[part 1 of 2: packages /VehicleProject to /Cluster]
AUTOSAR XML (schema 00048)
standard types defined: boolean, sint16, sint8, uint16, uint32, uint8
package /VehicleProject
  system System
package /TP
  can tp config KAMA_FP_EPT_0303_CAN: communication-cluster=KAMA_FP_EPT_0303, can-tp-ecu{cycle-time-main-function=0.005, ecu-instance=VCU}
    can tp channel TPCH: channel-id=1, channel-mode=FULL-DUPLEX-MODE
    can-tp-connection addressing-format=STANDARD, can-tp-channel=TPCH, data-pdu=AllFunctionRequest_Tp_oKAMA_FP_EPT_0303, receiver=TN_VCU, ta-type=FUNCTIONAL, tp-sdu=AllFunctionRequest_oKAMA_FP_EPT_0303, transmitter=TN_Diag:
      ident AllFunctionRequest_oTN_Diag
    can-tp-connection addressing-format=STANDARD, can-tp-channel=TPCH, data-pdu=OBDFunRequest_Tp_oKAMA_FP_EPT_0303, receiver=TN_VCU, ta-type=FUNCTIONAL, tp-sdu=OBDFunRequest_oKAMA_FP_EPT_0303, transmitter=TN_OBDDiag:
      ident OBDFunRequest_oTN_OBDDiag
    can-tp-connection addressing-format=STANDARD, can-tp-channel=TPCH, data-pdu=UDSFunRequest_Tp_oKAMA_FP_EPT_0303, receiver=TN_VCU, ta-type=FUNCTIONAL, tp-sdu=UDSFunRequest_oKAMA_FP_EPT_0303, transmitter=TN_Diag:
      ident UDSFunRequest_oTN_Diag
    can-tp-connection addressing-format=STANDARD, can-tp-channel=TPCH, data-pdu=OBDRequest_Tp_oKAMA_FP_EPT_0303, flow-control-pdu=OBDResponse_Tp_oKAMA_FP_EPT_0303, receiver=TN_VCU, ta-type=PHYSICAL, tp-sdu=OBDRequest_oKAMA_FP_EPT_0303, transmitter=TN_OBDDiag:
      ident OBDRequest_oTN_VCU
    can-tp-connection addressing-format=STANDARD, can-tp-channel=TPCH, data-pdu=OBDResponse_Tp_oKAMA_FP_EPT_0303, flow-control-pdu=OBDRequest_Tp_oKAMA_FP_EPT_0303, receiver=TN_OBDDiag, ta-type=PHYSICAL, tp-sdu=OBDResponse_oKAMA_FP_EPT_0303, transmitter=TN_VCU:
      ident OBDResponse_oTN_VCU
    can-tp-connection addressing-format=STANDARD, can-tp-channel=TPCH, data-pdu=UDSRequest_Tp_oKAMA_FP_EPT_0303, flow-control-pdu=UDSResponse_Tp_oKAMA_FP_EPT_0303, receiver=TN_VCU, ta-type=PHYSICAL, tp-sdu=UDSRequest_oKAMA_FP_EPT_0303, transmitter=TN_Diag:
      ident UDSRequest_oTN_VCU
    can-tp-connection addressing-format=STANDARD, can-tp-channel=TPCH, data-pdu=UDSResponse_Tp_oKAMA_FP_EPT_0303, flow-control-pdu=UDSRequest_Tp_oKAMA_FP_EPT_0303, receiver=TN_Diag, ta-type=PHYSICAL, tp-sdu=UDSResponse_oKAMA_FP_EPT_0303, transmitter=TN_VCU:
      ident UDSResponse_oTN_VCU
    can tp node TN_Diag
    can tp node TN_OBDDiag
    can tp node TN_VCU: connector=CN_KAMA_FP_EPT_0303
package /Cluster
  can cluster KAMA_FP_EPSChassis1_0303: baudrate=500000, protocol-name=CAN
    can physical channel CHNL: comm-connectors=CN_KAMA_FP_EPSChassis1_0303
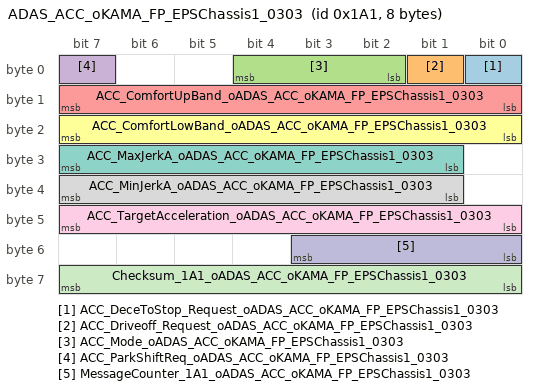
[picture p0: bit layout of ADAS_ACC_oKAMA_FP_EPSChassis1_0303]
      frame ADAS_ACC_oKAMA_FP_EPSChassis1_0303: id 0x1A1, to VCU, frame-length=8, can-addressing-mode=STANDARD
        pdu ADAS_ACC_oKAMA_FP_EPSChassis1_0303: length=8, minimum-delay=0, transmission-mode-false-timing=cyclic-timing={time-offset=0, time-period=0.02}, transmission-mode-true-timing=cyclic-timing={time-offset=0, time-period=0.02}, unused-bit-pattern=0
          signal ACC_DeceToStop_Request_oADAS_ACC_oKAMA_FP_EPSChassis1_0303: start 0, 1 bit, big-endian, i-signal-type=PRIMITIVE, init-value=0, base-type=boolean, compu {0=Cx0_no_demand (no demand), 1=Cx1_demand}, range raw 0..1, transfer-property=PENDING, to VCU
          signal ACC_Driveoff_Request_oADAS_ACC_oKAMA_FP_EPSChassis1_0303: start 1, 1 bit, big-endian, i-signal-type=PRIMITIVE, init-value=0, base-type=boolean, compu {0=Cx0_no_demand (no demand), 1=Cx1_demand}, range raw 0..1, transfer-property=PENDING, to VCU
          signal ACC_Mode_oADAS_ACC_oKAMA_FP_EPSChassis1_0303: start 4, 3 bit, big-endian, i-signal-type=PRIMITIVE, init-value=0, base-type=uint8, compu {0=Cx0_Off, 1=Cx1_passive, 2=Cx2_Standby, 3=Cx3_active, 4=Cx4_BrakeOnly, 5=Cx5_Override, 6=Cx6_Standstill, 7=Cx7_Failure}, range raw 0..7, transfer-property=PENDING, to VCU
          signal ACC_ParkShiftReq_oADAS_ACC_oKAMA_FP_EPSChassis1_0303: start 7, 1 bit, big-endian, i-signal-type=PRIMITIVE, init-value=0, base-type=boolean, compu {0=Cx0_No_Request_ (No Request), 1=Cx1_Request_Park_Shif (Request; Park Shif)}, range raw 0..1, transfer-property=PENDING, to VCU
          signal ACC_ComfortUpBand_oADAS_ACC_oKAMA_FP_EPSChassis1_0303: start 15, 8 bit, big-endian, i-signal-type=PRIMITIVE, init-value=140, base-type=uint8, compu {0=Cx00_no_demand (no demand), 1=Cx01_demand, phys=raw*0.05-7 for raw 2..255}, range raw 0..255, transfer-property=PENDING, to VCU
          signal ACC_ComfortLowBand_oADAS_ACC_oKAMA_FP_EPSChassis1_0303: start 23, 8 bit, big-endian, i-signal-type=PRIMITIVE, init-value=140, base-type=uint8, compu {phys=raw*0.05-7 for raw 0..255}, range raw 0..255, transfer-property=PENDING, to VCU
          signal ACC_MaxJerkA_oADAS_ACC_oKAMA_FP_EPSChassis1_0303: start 31, 7 bit, big-endian, i-signal-type=PRIMITIVE, init-value=0, base-type=uint8, compu {phys=raw*0.2 for raw 0..127}, range raw 0..127, transfer-property=PENDING, to VCU
          signal ACC_MinJerkA_oADAS_ACC_oKAMA_FP_EPSChassis1_0303: start 39, 7 bit, big-endian, i-signal-type=PRIMITIVE, init-value=127, base-type=uint8, compu {phys=raw*0.2-25.4 for raw 0..127}, range raw 0..127, transfer-property=PENDING, to VCU
          signal ACC_TargetAcceleration_oADAS_ACC_oKAMA_FP_EPSChassis1_0303: start 47, 8 bit, big-endian, i-signal-type=PRIMITIVE, init-value=140, base-type=uint8, compu {phys=raw*0.05-7 for raw 0..255; unit m/s^2}, range raw 0..255, unit=m/s^2, transfer-property=PENDING, to VCU
          signal MessageCounter_1A1_oADAS_ACC_oKAMA_FP_EPSChassis1_0303: start 51, 4 bit, big-endian, i-signal-type=PRIMITIVE, init-value=0, base-type=uint8, compu {identical}, range raw 0..15, transfer-property=PENDING, to VCU
          signal Checksum_1A1_oADAS_ACC_oKAMA_FP_EPSChassis1_0303: start 63, 8 bit, big-endian, i-signal-type=PRIMITIVE, init-value=0, base-type=uint8, compu {identical}, range raw 0..255, transfer-property=PENDING, to VCU
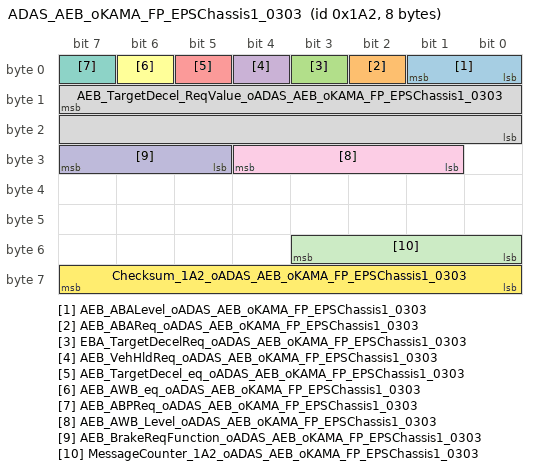
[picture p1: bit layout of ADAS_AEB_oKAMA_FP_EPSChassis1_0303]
      frame ADAS_AEB_oKAMA_FP_EPSChassis1_0303: id 0x1A2, to VCU, frame-length=8, can-addressing-mode=STANDARD
        pdu ADAS_AEB_oKAMA_FP_EPSChassis1_0303: length=8, minimum-delay=0, transmission-mode-false-timing=cyclic-timing={time-offset=0, time-period=0.02}, transmission-mode-true-timing=cyclic-timing={time-offset=0, time-period=0.02}, unused-bit-pattern=0
          signal AEB_ABALevel_oADAS_AEB_oKAMA_FP_EPSChassis1_0303: start 1, 2 bit, big-endian, i-signal-type=PRIMITIVE, init-value=0, base-type=uint8, compu {0=Cx0_Level_0_ (Level 0), 1=Cx1_Level_1 (Level 1), 2=Cx2_Level_2 (Level 2), 3=Cx3_Level_3 (Level 3)}, range raw 0..3, transfer-property=PENDING, to VCU
          signal AEB_ABAReq_oADAS_AEB_oKAMA_FP_EPSChassis1_0303: start 2, 1 bit, big-endian, i-signal-type=PRIMITIVE, init-value=0, base-type=boolean, compu {0=Cx0_No_Request_ (No Request), 1=Cx1_Request}, range raw 0..1, transfer-property=PENDING, to VCU
          signal EBA_TargetDecelReq_oADAS_AEB_oKAMA_FP_EPSChassis1_0303: start 3, 1 bit, big-endian, i-signal-type=PRIMITIVE, init-value=0, base-type=boolean, compu {0=Cx0_No_Request_ (No Request), 1=Cx1_Request}, range raw 0..1, transfer-property=PENDING, to VCU
          signal AEB_VehHldReq_oADAS_AEB_oKAMA_FP_EPSChassis1_0303: start 4, 1 bit, big-endian, i-signal-type=PRIMITIVE, init-value=0, base-type=boolean, compu {0=Cx0_No_Request_ (No Request), 1=Cx1_Request}, range raw 0..1, transfer-property=PENDING, to VCU
          signal AEB_TargetDecel_eq_oADAS_AEB_oKAMA_FP_EPSChassis1_0303: start 5, 1 bit, big-endian, i-signal-type=PRIMITIVE, init-value=0, base-type=boolean, compu {0=Cx0_No_Request_ (No Request), 1=Cx1_Request}, range raw 0..1, transfer-property=PENDING, to VCU
          signal AEB_AWB_eq_oADAS_AEB_oKAMA_FP_EPSChassis1_0303: start 6, 1 bit, big-endian, i-signal-type=PRIMITIVE, init-value=0, base-type=boolean, compu {0=Cx0_No_Request_ (No Request), 1=Cx1_Request}, range raw 0..1, transfer-property=PENDING, to VCU
          signal AEB_ABPReq_oADAS_AEB_oKAMA_FP_EPSChassis1_0303: start 7, 1 bit, big-endian, i-signal-type=PRIMITIVE, init-value=0, base-type=boolean, compu {0=Cx0_No_Request_ (No Request), 1=Cx1_Request}, range raw 0..1, transfer-property=PENDING, to VCU
          signal AEB_TargetDecel_ReqValue_oADAS_AEB_oKAMA_FP_EPSChassis1_0303: start 15, 16 bit, big-endian, i-signal-type=PRIMITIVE, init-value=0, base-type=uint16, compu {0=Cx0000_Valid_value_ (Valid value), 21813=Cx5535_Invalid, phys=raw*0.000488-16 for raw 1..65535; unit m/s2}, range raw 0..65535, unit=m/s2, transfer-property=PENDING, to VCU
          signal AEB_AWB_Level_oADAS_AEB_oKAMA_FP_EPSChassis1_0303: start 28, 4 bit, big-endian, i-signal-type=PRIMITIVE, init-value=0, base-type=uint8, compu {0=Cx0_No_level_ (No level), 1=Cx1_Level_1 (Level 1), 2=Cx2_Level_2 (Level 2), 3=Cx3_Level_3 (Level 3), 4=Cx4_Level_4 (Level 4), 5=Cx5_Resvered}, range raw 0..15, transfer-property=PENDING, to VCU
          signal AEB_BrakeReqFunction_oADAS_AEB_oKAMA_FP_EPSChassis1_0303: start 31, 3 bit, big-endian, i-signal-type=PRIMITIVE, init-value=0, base-type=uint8, compu {0=Cx0_No_Request_ (No Request), 1=Cx1_AEB_V (AEB-V), 2=Cx2_AEB_VRU (AEB-VRU), 3=Cx3_AEB_JA (AEB-JA), 4=Cx4_Reserved, 5=Cx5_AEB_FCTB (AEB-FCTB), 6=Cx6_Reserved}, range raw 0..7, transfer-property=PENDING, to VCU
          signal MessageCounter_1A2_oADAS_AEB_oKAMA_FP_EPSChassis1_0303: start 51, 4 bit, big-endian, i-signal-type=PRIMITIVE, init-value=0, base-type=uint8, compu {identical}, range raw 0..15, transfer-property=PENDING, to VCU
          signal Checksum_1A2_oADAS_AEB_oKAMA_FP_EPSChassis1_0303: start 63, 8 bit, big-endian, i-signal-type=PRIMITIVE, init-value=0, base-type=uint8, compu {identical}, range raw 0..255, transfer-property=PENDING, to VCU
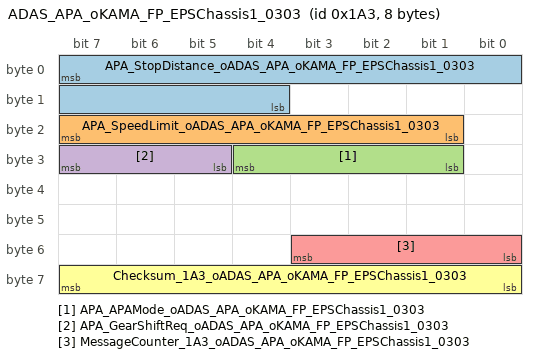
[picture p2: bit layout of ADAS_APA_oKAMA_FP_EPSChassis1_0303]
      frame ADAS_APA_oKAMA_FP_EPSChassis1_0303: id 0x1A3, to VCU, frame-length=8, can-addressing-mode=STANDARD
        pdu ADAS_APA_oKAMA_FP_EPSChassis1_0303: length=8, minimum-delay=0, transmission-mode-false-timing=cyclic-timing={time-offset=0, time-period=0.02}, transmission-mode-true-timing=cyclic-timing={time-offset=0, time-period=0.02}, unused-bit-pattern=0
          signal APA_StopDistance_oADAS_APA_oKAMA_FP_EPSChassis1_0303: start 7, 12 bit, big-endian, i-signal-type=PRIMITIVE, init-value=0, base-type=uint16, compu {identical}, range raw 0..4095, unit=cm, transfer-property=PENDING, to VCU
          signal APA_SpeedLimit_oADAS_APA_oKAMA_FP_EPSChassis1_0303: start 23, 7 bit, big-endian, i-signal-type=PRIMITIVE, init-value=0, base-type=uint8, compu {phys=raw*0.1 for raw 0..127; unit kph}, range raw 0..127, unit=kph, transfer-property=PENDING, to VCU
          signal APA_APAMode_oADAS_APA_oKAMA_FP_EPSChassis1_0303: start 28, 4 bit, big-endian, i-signal-type=PRIMITIVE, init-value=0, base-type=uint8, compu {0=Cx0_Init, 1=Cx1_Standby, 2=Cx2_Active, 3=Cx3_Maneuver_Finished (Maneuver Finished), 4=Cx4_Suspend, 5=Cx5_Abort, 10=CxA_Off}, range raw 0..15, transfer-property=PENDING, to VCU
          signal APA_GearShiftReq_oADAS_APA_oKAMA_FP_EPSChassis1_0303: start 31, 3 bit, big-endian, i-signal-type=PRIMITIVE, init-value=0, base-type=uint8, compu {0=Cx0_No_Request (No Request), 1=Cx1_P, 2=Cx2_R, 3=Cx3_N, 4=Cx4_D}, range raw 0..7, transfer-property=PENDING, to VCU
          signal MessageCounter_1A3_oADAS_APA_oKAMA_FP_EPSChassis1_0303: start 51, 4 bit, big-endian, i-signal-type=PRIMITIVE, init-value=0, base-type=uint8, compu {identical}, range raw 0..15, transfer-property=PENDING, to VCU
          signal Checksum_1A3_oADAS_APA_oKAMA_FP_EPSChassis1_0303: start 63, 8 bit, big-endian, i-signal-type=PRIMITIVE, init-value=0, base-type=uint8, compu {identical}, range raw 0..255, transfer-property=PENDING, to VCU
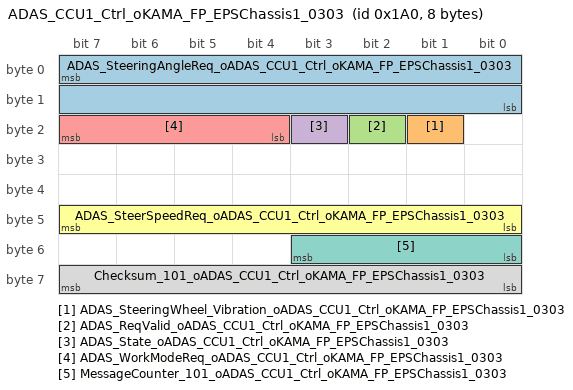
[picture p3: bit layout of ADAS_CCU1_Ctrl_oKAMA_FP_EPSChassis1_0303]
      frame ADAS_CCU1_Ctrl_oKAMA_FP_EPSChassis1_0303: id 0x1A0, to VCU, frame-length=8, can-addressing-mode=STANDARD
        pdu ADAS_CCU1_Ctrl_oKAMA_FP_EPSChassis1_0303: length=8, minimum-delay=0, transmission-mode-false-timing=cyclic-timing={time-offset=0, time-period=0.02}, transmission-mode-true-timing=cyclic-timing={time-offset=0, time-period=0.02}, unused-bit-pattern=0
          signal ADAS_SteeringAngleReq_oADAS_CCU1_Ctrl_oKAMA_FP_EPSChassis1_0303: start 7, 16 bit, big-endian, i-signal-type=PRIMITIVE, init-value=7380, base-type=uint16, compu {phys=raw*0.1-738 for raw 0..14760; unit deg}, range raw 0..14760, unit=deg, transfer-property=PENDING, to VCU  # ADAS request Steering wheel steering target angle ·½ÏòÅÌ×ªÏòÄ¿±ê½Ç¶È
          signal ADAS_SteeringWheel_Vibration_oADAS_CCU1_Ctrl_oKAMA_FP_EPSChassis1_0303: start 17, 1 bit, big-endian, i-signal-type=PRIMITIVE, init-value=0, base-type=boolean, compu {0=Cx0_InValid_ (InValid;), 1=Cx1_Valid}, range raw 0..1, transfer-property=PENDING, to VCU
          signal ADAS_ReqValid_oADAS_CCU1_Ctrl_oKAMA_FP_EPSChassis1_0303: start 18, 1 bit, big-endian, i-signal-type=PRIMITIVE, init-value=0, base-type=boolean, compu {0=Cx0_InValid_ (InValid;), 1=Cx1_Valid}, range raw 0..1, transfer-property=PENDING, to VCU  # ADAS angle request valid status ×ª½ÇÖ¸ÁîÓÐÐ§Î»
          signal ADAS_State_oADAS_CCU1_Ctrl_oKAMA_FP_EPSChassis1_0303: start 19, 1 bit, big-endian, i-signal-type=PRIMITIVE, init-value=0, base-type=boolean, compu {0=Cx0_InValid_ (InValid;), 1=Cx1_Valid}, range raw 0..1, transfer-property=PENDING, to VCU  # ADAS valid status ×´Ì¬ÓÐÐ§Î»
          signal ADAS_WorkModeReq_oADAS_CCU1_Ctrl_oKAMA_FP_EPSChassis1_0303: start 23, 4 bit, big-endian, i-signal-type=PRIMITIVE, init-value=0, base-type=uint8, compu {0=Cx0_reserve, 1=Cx1_AutoSteering_Mode (AutoSteering Mode), 4=Cx4_DriverSteering_Mode_ (DriverSteering Mode), 5=Cx5_Intervent_Recove (Intervent Recove)}, range raw 0..15, transfer-property=PENDING, to VCU  # ADAS request steering work mode ¿ØÖÆÆ÷¹¤×÷Ä£Ê½Ö¸Áî
          signal ADAS_SteerSpeedReq_oADAS_CCU1_Ctrl_oKAMA_FP_EPSChassis1_0303: start 47, 8 bit, big-endian, i-signal-type=PRIMITIVE, init-value=0, base-type=uint8, compu {0=Cx00_InValid_ (InValid;), 1=Cx01_Valid, phys=raw*10 for raw 2..54; unit deg/s}, range raw 0..54, unit=deg/s, transfer-property=PENDING, to VCU  # ADAS request Steering wheel steering target angular speed ·½ÏòÅÌ×ªÏòÄ¿±ê½ÇËÙ¶È
          signal MessageCounter_101_oADAS_CCU1_Ctrl_oKAMA_FP_EPSChassis1_0303: start 51, 4 bit, big-endian, i-signal-type=PRIMITIVE, init-value=0, base-type=uint8, compu {identical}, range raw 0..15, transfer-property=PENDING, to VCU  # Alive Counter ´Ó0µ½15Ñ­»·¼ÆÊý
          signal Checksum_101_oADAS_CCU1_Ctrl_oKAMA_FP_EPSChassis1_0303: start 63, 8 bit, big-endian, i-signal-type=PRIMITIVE, init-value=0, base-type=uint8, compu {identical}, range raw 0..255, transfer-property=PENDING, to VCU
      frame DonorCar_ACM_Status_oKAMA_FP_EPSChassis1_0303: id 0x380, to VCU, frame-length=8, can-addressing-mode=STANDARD
        pdu DonorCar_ACM_Status_oKAMA_FP_EPSChassis1_0303: length=8, minimum-delay=0, transmission-mode-false-timing=cyclic-timing={time-offset=0, time-period=0.02}, transmission-mode-true-timing=cyclic-timing={time-offset=0, time-period=0.02}, unused-bit-pattern=0
          signal ACU_DrvSeatbeltBucklestatus_oDonorCar_ACM_Status_oKAMA_FP_EPSChassis1_0303: start 0, 1 bit, big-endian, i-signal-type=PRIMITIVE, init-value=0, base-type=boolean, compu {0=Cx0_Off, 1=Cx1_Bucked}, range raw 0..1, transfer-property=PENDING, to VCU
          signal ACU_PassSeatbeltBucklestatus_oDonorCar_ACM_Status_oKAMA_FP_EPSChassis1_0303: start 1, 1 bit, big-endian, i-signal-type=PRIMITIVE, init-value=0, base-type=boolean, compu {0=Cx0_Off, 1=Cx1_Bucked}, range raw 0..1, transfer-property=PENDING, to VCU
      frame DonorCar_BCM_LDoorWindowState_oKAMA_FP_EPSChassis1_0303: id 0x285, to VCU, frame-length=8, can-addressing-mode=STANDARD
        pdu DonorCar_BCM_LDoorWindowState_oKAMA_FP_EPSChassis1_0303: length=8, minimum-delay=0, transmission-mode-false-timing=cyclic-timing={time-offset=0, time-period=0.1}, transmission-mode-true-timing=cyclic-timing={time-offset=0, time-period=0.1}, unused-bit-pattern=0
          signal BCM_FrontLeftDoorAjarStatus_oDonorCar_BCM_LDoorWindowState_oKAMA_FP_EPSChassis1_0303: start 32, 1 bit, big-endian, i-signal-type=PRIMITIVE, init-value=0, base-type=boolean, compu {identical}, range raw 0..1, transfer-property=PENDING, to VCU
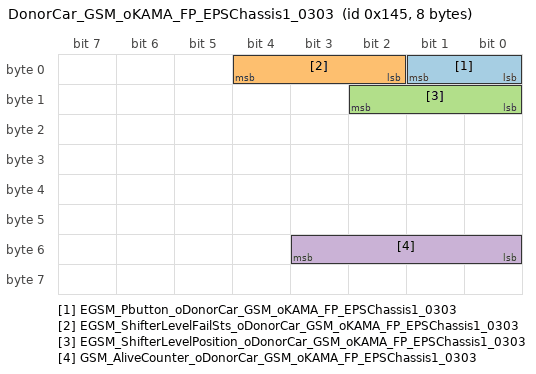
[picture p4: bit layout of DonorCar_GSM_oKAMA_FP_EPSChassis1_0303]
      frame DonorCar_GSM_oKAMA_FP_EPSChassis1_0303: id 0x145, to VCU, frame-length=8, can-addressing-mode=STANDARD
        pdu DonorCar_GSM_oKAMA_FP_EPSChassis1_0303: length=8, minimum-delay=0, transmission-mode-false-timing=cyclic-timing={time-offset=0, time-period=0.02}, transmission-mode-true-timing=cyclic-timing={time-offset=0, time-period=0.02}, unused-bit-pattern=0
          signal EGSM_Pbutton_oDonorCar_GSM_oKAMA_FP_EPSChassis1_0303: start 1, 2 bit, big-endian, i-signal-type=PRIMITIVE, init-value=0, base-type=uint8, compu {0=Cx0_Not_Pressed (Not Pressed), 1=Cx1_Pressed}, range raw 0..3, transfer-property=PENDING, to VCU
          signal EGSM_ShifterLevelFailSts_oDonorCar_GSM_oKAMA_FP_EPSChassis1_0303: start 4, 3 bit, big-endian, i-signal-type=PRIMITIVE, init-value=0, base-type=uint8, compu {0=Cx0_No_Fault (No Fault), 1=Cx1_Fault_Level1 (Fault Level1), 2=Cx2_Fault_Level2 (Fault Level2)}, range raw 0..7, transfer-property=PENDING, to VCU
          signal EGSM_ShifterLevelPosition_oDonorCar_GSM_oKAMA_FP_EPSChassis1_0303: start 10, 3 bit, big-endian, i-signal-type=PRIMITIVE, init-value=0, base-type=uint8, compu {0=Cx0_Default, 1=Cx1_Left_1 (Left 1), 2=Cx2_Right_1 (Right 1), 3=Cx3_Left_2 (Left 2), 4=Cx4_Right_2 (Right 2)}, range raw 0..7, transfer-property=PENDING, to VCU
          signal GSM_AliveCounter_oDonorCar_GSM_oKAMA_FP_EPSChassis1_0303: start 51, 4 bit, big-endian, i-signal-type=PRIMITIVE, init-value=0, base-type=uint8, compu {identical}, range raw 0..15, transfer-property=PENDING, to VCU  # message alive counter
      frame DonorCar_MMI_Status_Infor_oKAMA_FP_EPSChassis1_0303: id 0x2A4, to VCU, frame-length=8, can-addressing-mode=STANDARD
        pdu DonorCar_MMI_Status_Infor_oKAMA_FP_EPSChassis1_0303: length=8, minimum-delay=0, transmission-mode-false-timing=cyclic-timing={time-offset=0, time-period=0.1}, transmission-mode-true-timing=cyclic-timing={time-offset=0, time-period=0.1}, unused-bit-pattern=0
          signal MMI_DriverModeReq_oDonorCar_MMI_Status_Infor_oKAMA_FP_EPSChassis1_0303: start 42, 3 bit, big-endian, i-signal-type=PRIMITIVE, init-value=0, base-type=uint8, compu {0=Cx0_ECO_Mode (ECO Mode), 1=Cx1_Reserved, 2=Cx2_Sport}, range raw 0..7, transfer-property=PENDING, to VCU
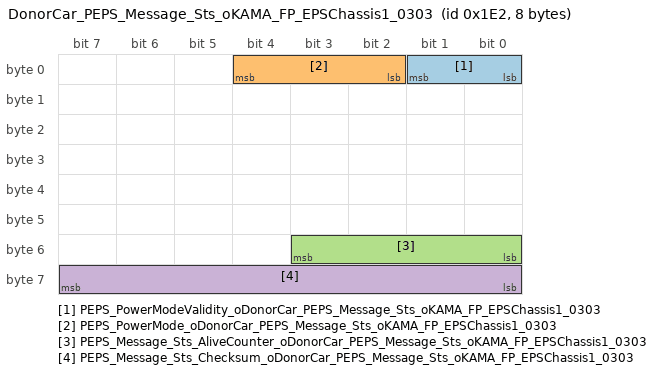
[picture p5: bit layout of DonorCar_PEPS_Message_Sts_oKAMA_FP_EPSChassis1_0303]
      frame DonorCar_PEPS_Message_Sts_oKAMA_FP_EPSChassis1_0303: id 0x1E2, to VCU, frame-length=8, can-addressing-mode=STANDARD
        pdu DonorCar_PEPS_Message_Sts_oKAMA_FP_EPSChassis1_0303: length=8, minimum-delay=0, transmission-mode-false-timing=cyclic-timing={time-offset=0, time-period=0.02}, transmission-mode-true-timing=cyclic-timing={time-offset=0, time-period=0.02}, unused-bit-pattern=0
          signal PEPS_PowerModeValidity_oDonorCar_PEPS_Message_Sts_oKAMA_FP_EPSChassis1_0303: start 1, 2 bit, big-endian, i-signal-type=PRIMITIVE, init-value=0, base-type=uint8, compu {identical}, range raw 0..3, transfer-property=PENDING, to VCU  # PEPS Power Distribution StatusValidity bit
          signal PEPS_PowerMode_oDonorCar_PEPS_Message_Sts_oKAMA_FP_EPSChassis1_0303: start 4, 3 bit, big-endian, i-signal-type=PRIMITIVE, init-value=0, base-type=uint8, compu {0=Cx0_Off, 1=Cx1_ACC, 2=Cx2_On, 3=Cx3_Reserved}, range raw 0..7, transfer-property=PENDING, to VCU  # PEPS Power Distribution Status
          signal PEPS_Message_Sts_AliveCounter_oDonorCar_PEPS_Message_Sts_oKAMA_FP_EPSChassis1_0303: start 51, 4 bit, big-endian, i-signal-type=PRIMITIVE, init-value=0, base-type=uint8, compu {identical}, range raw 0..15, transfer-property=PENDING, to VCU  # message alive counter
          signal PEPS_Message_Sts_Checksum_oDonorCar_PEPS_Message_Sts_oKAMA_FP_EPSChassis1_0303: start 63, 8 bit, big-endian, i-signal-type=PRIMITIVE, init-value=0, base-type=uint8, compu {identical}, range raw 0..255, transfer-property=PENDING, to VCU  # message checksum
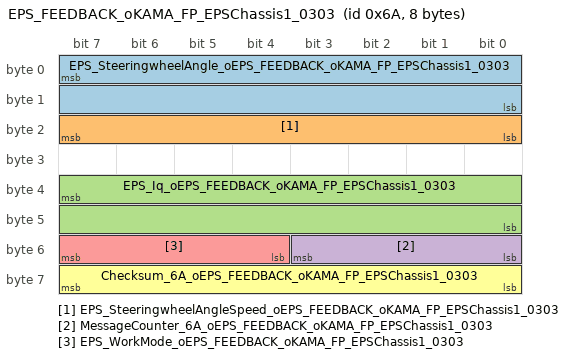
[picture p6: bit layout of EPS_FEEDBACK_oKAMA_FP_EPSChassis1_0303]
      frame EPS_FEEDBACK_oKAMA_FP_EPSChassis1_0303: id 0x6A, to VCU, frame-length=8, can-addressing-mode=STANDARD
        pdu EPS_FEEDBACK_oKAMA_FP_EPSChassis1_0303: length=8, minimum-delay=0, transmission-mode-false-timing=cyclic-timing={time-offset=0, time-period=0.02}, transmission-mode-true-timing=cyclic-timing={time-offset=0, time-period=0.02}, unused-bit-pattern=0
          signal EPS_SteeringwheelAngle_oEPS_FEEDBACK_oKAMA_FP_EPSChassis1_0303: start 7, 16 bit, big-endian, i-signal-type=PRIMITIVE, init-value=7380, base-type=uint16, compu {phys=raw*0.1-738 for raw 0..14760; unit deg}, range raw 0..14760, unit=deg, transfer-property=PENDING, to VCU  # Steering wheel angle ·½ÏòÅÌ×ªÏò½Ç¶È
          signal EPS_SteeringwheelAngleSpeed_oEPS_FEEDBACK_oKAMA_FP_EPSChassis1_0303: start 23, 8 bit, big-endian, i-signal-type=PRIMITIVE, init-value=0, base-type=uint8, compu {phys=raw*10 for raw 0..54; unit deg/s}, range raw 0..54, unit=deg/s, transfer-property=PENDING, to VCU  # Steering wheel angle Speed ·½ÏòÅÌ×ªÏò½ÇËÙ¶È
          signal EPS_Iq_oEPS_FEEDBACK_oKAMA_FP_EPSChassis1_0303: start 39, 16 bit, big-endian, i-signal-type=PRIMITIVE, init-value=10000, base-type=uint16, compu {phys=raw*0.25-2500 for raw 0..20000}, range raw 0..20000, transfer-property=PENDING, to VCU  # Steering Iq current ×ªÏòqÖá·´À¡µçÁ÷
          signal MessageCounter_6A_oEPS_FEEDBACK_oKAMA_FP_EPSChassis1_0303: start 51, 4 bit, big-endian, i-signal-type=PRIMITIVE, init-value=0, base-type=uint8, compu {identical}, range raw 0..15, transfer-property=PENDING, to VCU  # Alive Counter ´Ó0µ½15Ñ­»·¼ÆÊý
          signal EPS_WorkMode_oEPS_FEEDBACK_oKAMA_FP_EPSChassis1_0303: start 55, 4 bit, big-endian, i-signal-type=PRIMITIVE, init-value=0, base-type=uint8, compu {0=Cx0_Reserved, 1=Cx1_AutoSteering_Mode (AutoSteering Mode), 2=Cx2_Reserved, 3=Cx3_Reserved, 4=Cx4_DriverSteering_Mode (DriverSteering Mode), 5=Cx5_Intervent_Recover (Intervent Recover), 6=Cx6_Warning_Mode (Warning Mode), 7=Cx7_Erorr_Mode (Erorr Mode), 8=Cx8_Reserved}, range raw 0..15, transfer-property=PENDING, to VCU  # EPS Working mode EPS¹¤×÷Ä£Ê½
          signal Checksum_6A_oEPS_FEEDBACK_oKAMA_FP_EPSChassis1_0303: start 63, 8 bit, big-endian, i-signal-type=PRIMITIVE, init-value=0, base-type=uint8, compu {identical}, range raw 0..255, transfer-property=PENDING, to VCU
      frame GW_TCU_AmbientTemp_oKAMA_FP_EPSChassis1_0303: id 0x2C2, to VCU, frame-length=8, can-addressing-mode=STANDARD
        pdu GW_TCU_AmbientTemp_oKAMA_FP_EPSChassis1_0303: length=8, minimum-delay=0, transmission-mode-false-timing=cyclic-timing={time-offset=0, time-period=1}, transmission-mode-true-timing=cyclic-timing={time-offset=0, time-period=1}, unused-bit-pattern=0
          signal TCU_ambientTemperature_oGW_TCU_AmbientTemp_oKAMA_FP_EPSChassis1_0303: start 7, 8 bit, big-endian, i-signal-type=PRIMITIVE, init-value=50, base-type=uint8, compu {phys=raw-50 for raw 0..255}, range raw 0..255, transfer-property=PENDING, to VCU
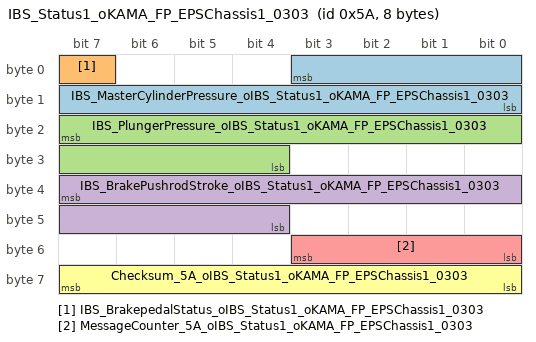
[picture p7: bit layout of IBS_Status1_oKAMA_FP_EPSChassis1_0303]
      frame IBS_Status1_oKAMA_FP_EPSChassis1_0303: id 0x5A, to VCU, frame-length=8, can-addressing-mode=STANDARD
        pdu IBS_Status1_oKAMA_FP_EPSChassis1_0303: length=8, minimum-delay=0, transmission-mode-false-timing=cyclic-timing={time-offset=0, time-period=0.02}, transmission-mode-true-timing=cyclic-timing={time-offset=0, time-period=0.02}, unused-bit-pattern=0
          signal IBS_MasterCylinderPressure_oIBS_Status1_oKAMA_FP_EPSChassis1_0303: start 3, 12 bit, big-endian, i-signal-type=PRIMITIVE, init-value=0, base-type=uint16, compu {phys=raw*0.1 for raw 0..2500; unit BAR}, range raw 0..2500, unit=BAR, transfer-property=PENDING, to VCU  # EN:Master Cylinder Pressure signal CH£ºÖ÷¸×Ñ¹Á¦ÊýÖµ
          signal IBS_BrakepedalStatus_oIBS_Status1_oKAMA_FP_EPSChassis1_0303: start 7, 1 bit, big-endian, i-signal-type=PRIMITIVE, init-value=0, base-type=boolean, compu {0=Cx0_No_pressed (No pressed), 1=Cx1_pressed}, range raw 0..1, transfer-property=PENDING, to VCU
          signal IBS_PlungerPressure_oIBS_Status1_oKAMA_FP_EPSChassis1_0303: start 23, 12 bit, big-endian, i-signal-type=PRIMITIVE, init-value=0, base-type=uint16, compu {phys=raw*0.1 for raw 0..2500; unit BAR}, range raw 0..2500, unit=BAR, transfer-property=PENDING, to VCU  # pressure of PSU
          signal IBS_BrakePushrodStroke_oIBS_Status1_oKAMA_FP_EPSChassis1_0303: start 39, 12 bit, big-endian, i-signal-type=PRIMITIVE, init-value=320, base-type=uint16, compu {phys=raw/64-5 for raw 0..3328; unit mm}, range raw 0..3328, unit=mm, transfer-property=PENDING, to VCU  # IBS pushrod stroke
          signal MessageCounter_5A_oIBS_Status1_oKAMA_FP_EPSChassis1_0303: start 51, 4 bit, big-endian, i-signal-type=PRIMITIVE, init-value=0, base-type=uint8, compu {identical}, range raw 0..15, transfer-property=PENDING, to VCU
          signal Checksum_5A_oIBS_Status1_oKAMA_FP_EPSChassis1_0303: start 63, 8 bit, big-endian, i-signal-type=PRIMITIVE, init-value=0, base-type=uint8, compu {identical}, range raw 0..255, transfer-property=PENDING, to VCU
      frame IBS_Status2_oKAMA_FP_EPSChassis1_0303: id 0x5B, to VCU, frame-length=8, can-addressing-mode=STANDARD
        pdu IBS_Status2_oKAMA_FP_EPSChassis1_0303: length=8, minimum-delay=0, transmission-mode-false-timing=cyclic-timing={time-offset=0, time-period=0.02}, transmission-mode-true-timing=cyclic-timing={time-offset=0, time-period=0.02}, unused-bit-pattern=0
          signal IBS_EPBTxtdisplay_oIBS_Status2_oKAMA_FP_EPSChassis1_0303: start 3, 4 bit, big-endian, i-signal-type=PRIMITIVE, init-value=0, base-type=uint8, compu {0=Cx0_Notextmessage, 1=Cx1_Gradienttoohigh, 2=Cx2_Clampforcenotenough, 3=Cx3_Fastenseatbelt, 4=Cx4_Openparkbrakebyswitch, 5=Cx5_Pressbrakepedal, 6=Cx6_reserved, 15=CxF_Invalid}, range raw 0..15, transfer-property=PENDING, to VCU  # EN: EPB Text display CH: EPBÎÄ×ÖÌáÊ¾
          signal IBS_BrakeLightRequest_oIBS_Status2_oKAMA_FP_EPSChassis1_0303: start 5, 2 bit, big-endian, i-signal-type=PRIMITIVE, init-value=0, base-type=uint8, compu {0=Cx0_brakelightOFF, 1=Cx1_brakelightON, 2=Cx2_notused, 3=Cx3_signal_not_available (signal not available)}, range raw 0..3, transfer-property=PENDING, to VCU  # EN:ESC request to illuminate the brake lights when the function is triggered CH:´¥·¢Ö÷¶¯ÖÆ¶¯Ê±£¬ESCÇëÇóµãÁÁÖÆ¶¯Î²µÆ
          signal IBS_EPBFailureLamp_oIBS_Status2_oKAMA_FP_EPSChassis1_0303: start 7, 2 bit, big-endian, i-signal-type=PRIMITIVE, init-value=0, base-type=uint8, compu {0=Cx0_LampOFF, 1=Cx1_LampON, 2=Cx2_flash, 3=Cx3_Invalid}, range raw 0..3, transfer-property=PENDING, to VCU  # EN: EPB Failure Lamp CH: ´íÎóÖ¸Ê¾µÆ
          signal EPB_failurestatus_oIBS_Status2_oKAMA_FP_EPSChassis1_0303: start 14, 1 bit, big-endian, i-signal-type=PRIMITIVE, init-value=0, base-type=boolean, compu {0=Cx0_No_Failure_ (No Failure;), 1=Cx1_Failure}, range raw 0..1, transfer-property=PENDING, to VCU  # EPB failure status
          signal BBF_failurestatus_oIBS_Status2_oKAMA_FP_EPSChassis1_0303: start 15, 1 bit, big-endian, i-signal-type=PRIMITIVE, init-value=0, base-type=boolean, compu {0=Cx0_No_Failure_ (No Failure;), 1=Cx1_Failure}, range raw 0..1, transfer-property=PENDING, to VCU  # BBF failure status
          signal IBS_EPBworkingStatus_oIBS_Status2_oKAMA_FP_EPSChassis1_0303: start 17, 2 bit, big-endian, i-signal-type=PRIMITIVE, init-value=0, base-type=uint8, compu {0=Cx0_both_brakes_released (both brakes released), 1=Cx1_both_brakes_applied (both brakes applied), 2=Cx2_both_brakes_in_operation (both brakes in operation), 3=Cx3_unknown}, range raw 0..3, transfer-property=PENDING, to VCU  # EN: EPB Status CH: EPB×´Ì¬
          signal IBS_HDCActive_oIBS_Status2_oKAMA_FP_EPSChassis1_0303: start 19, 2 bit, big-endian, i-signal-type=PRIMITIVE, init-value=0, base-type=uint8, compu {0=Cx0_OFF, 1=Cx1_ON, 2=Cx2_Standby, 3=Cx3_Error}, range raw 0..3, transfer-property=PENDING, to VCU  # EN:HDC Function Active CH:HDC ¹¦ÄÜ¼¤»î±êÖ¾Î»
          signal IBS_TCSActive_oIBS_Status2_oKAMA_FP_EPSChassis1_0303: start 24, 1 bit, big-endian, i-signal-type=PRIMITIVE, init-value=0, base-type=boolean, compu {0=Cx0_NotActive, 1=Cx1_Activ}, range raw 0..1, transfer-property=PENDING, to VCU  # EN:Tindicates TCS intervention active£¬TCS will detect spinning wheels and request torque reduction/limitation CH:CS¼¤»î±êÖ¾Î»
          signal IBS_VDCActive_oIBS_Status2_oKAMA_FP_EPSChassis1_0303: start 25, 1 bit, big-endian, i-signal-type=PRIMITIVE, init-value=0, base-type=boolean, compu {0=Cx0_NotActive, 1=Cx1_Active}, range raw 0..1, transfer-property=PENDING, to VCU  # EN:indicates VDC intervention active£¬ ESP will detect other vehicle slip/slide situations, and brake individual wheels to counteract the vehicle slid
          signal IBS_CDPActive_oIBS_Status2_oKAMA_FP_EPSChassis1_0303: start 26, 1 bit, big-endian, i-signal-type=PRIMITIVE, init-value=0, base-type=boolean, compu {0=Cx0_notactive, 1=Cx1_active}, range raw 0..1, transfer-property=PENDING, to VCU  # EN:CDP Function Active
          signal IBS_CDPAvailable_oIBS_Status2_oKAMA_FP_EPSChassis1_0303: start 27, 1 bit, big-endian, i-signal-type=PRIMITIVE, init-value=0, base-type=boolean, compu {0=Cx0_Valid, 1=Cx1_Invalid}, range raw 0..1, transfer-property=PENDING, to VCU  # EN:CDP Function Available CH:CDP ¹¦ÄÜ¿ÉÓÃ×´Ì¬
          signal IBS_HDCAvailable_oIBS_Status2_oKAMA_FP_EPSChassis1_0303: start 28, 1 bit, big-endian, i-signal-type=PRIMITIVE, init-value=0, base-type=boolean, compu {0=Cx0_Valid, 1=Cx1_Invalid}, range raw 0..1, transfer-property=PENDING, to VCU  # EN:HDC Function Available CH:HDC ¹¦ÄÜ¿ÉÓÃ×´Ì¬
          signal IBS_AEBActive_oIBS_Status2_oKAMA_FP_EPSChassis1_0303: start 29, 1 bit, big-endian, i-signal-type=PRIMITIVE, init-value=0, base-type=boolean, compu {0=Cx0_notactive, 1=Cx1_active}, range raw 0..1, transfer-property=PENDING, to VCU  # EN:AEB Function Active CH:AEB ¹¦ÄÜ¼¤»î±êÖ¾Î»
          signal IBS_ECDActive_oIBS_Status2_oKAMA_FP_EPSChassis1_0303: start 30, 1 bit, big-endian, i-signal-type=PRIMITIVE, init-value=0, base-type=boolean, compu {0=Cx0_notactive, 1=Cx1_active}, range raw 0..1, transfer-property=PENDING, to VCU  # EN:ECD Function Active CH:ECD ¹¦ÄÜ¼¤»î±êÖ¾Î»
          signal IBS_HHCActive_oIBS_Status2_oKAMA_FP_EPSChassis1_0303: start 31, 1 bit, big-endian, i-signal-type=PRIMITIVE, init-value=0, base-type=boolean, compu {0=Cx0_notactive, 1=Cx1_active}, range raw 0..1, transfer-property=PENDING, to VCU  # EN:HHC Function Active CH:HHC ¹¦ÄÜ¼¤»î±êÖ¾Î»
          signal IBS_HHCAvailable_oIBS_Status2_oKAMA_FP_EPSChassis1_0303: start 32, 1 bit, big-endian, i-signal-type=PRIMITIVE, init-value=0, base-type=boolean, compu {0=Cx0_notactive, 1=Cx1_active}, range raw 0..1, transfer-property=PENDING, to VCU  # EN:HHC Function Available CH:HHC ¹¦ÄÜ¿ÉÓÃ×´Ì¬
          signal IBS_AVHAvailable_oIBS_Status2_oKAMA_FP_EPSChassis1_0303: start 33, 1 bit, big-endian, i-signal-type=PRIMITIVE, init-value=0, base-type=boolean, compu {0=Cx0_Valid, 1=Cx1_Invalid}, range raw 0..1, transfer-property=PENDING, to VCU  # EN:AVH Function Available CH:AVH ¹¦ÄÜ¿ÉÓÃ×´Ì¬
          signal IBS_AVHActive_oIBS_Status2_oKAMA_FP_EPSChassis1_0303: start 34, 1 bit, big-endian, i-signal-type=PRIMITIVE, init-value=0, base-type=boolean, compu {0=Cx0_notactive, 1=Cx1_active}, range raw 0..1, transfer-property=PENDING, to VCU  # EN:AVH Function Active CH:AVH ¹¦ÄÜ¼¤»î±êÖ¾Î»
          signal IBS_LiquidAlarm_oIBS_Status2_oKAMA_FP_EPSChassis1_0303: start 35, 1 bit, big-endian, i-signal-type=PRIMITIVE, init-value=0, base-type=boolean, compu {0=Cx0_No_error (No error), 1=Cx1_Error}, range raw 0..1, transfer-property=PENDING, to VCU  # EN:Liquid level alarm signal CH:ÒºÎ»±¨¾¯ÐÅºÅ
          signal IBS_AVHStandbySts_oIBS_Status2_oKAMA_FP_EPSChassis1_0303: start 36, 1 bit, big-endian, i-signal-type=PRIMITIVE, init-value=0, base-type=boolean, compu {0=Cx0_notactive, 1=Cx1_activ}, range raw 0..1, transfer-property=PENDING, to VCU  # EN:AVH Function Standby CH:AVH ¹¦ÄÜ´ý»ú×´Ì¬
          signal IBS_EPBSwitchPositionValid_oIBS_Status2_oKAMA_FP_EPSChassis1_0303: start 37, 1 bit, big-endian, i-signal-type=PRIMITIVE, init-value=0, base-type=boolean, compu {0=Cx0_valid, 1=Cx1_error}, range raw 0..1, transfer-property=PENDING, to VCU  # EN: EPB Switch Position Valid CH:EPB¿ª¹ØÎ»ÖÃÓÐÐ§
          signal IBS_EPBSwitchPosition_oIBS_Status2_oKAMA_FP_EPSChassis1_0303: start 39, 2 bit, big-endian, i-signal-type=PRIMITIVE, init-value=0, base-type=uint8, compu {0=Cx0_no_request_ (no request£»), 1=Cx1_Release_request (Release request), 2=Cx2_Apply_request_ (Apply request£»), 3=Cx3_Error}, range raw 0..3, transfer-property=PENDING, to VCU  # EN: EPB Switch Position CH:EPB¿ª¹ØÎ»ÖÃ
          signal IBS_EPBFunctionLamp_oIBS_Status2_oKAMA_FP_EPSChassis1_0303: start 41, 2 bit, big-endian, i-signal-type=PRIMITIVE, init-value=0, base-type=uint8, compu {0=Cx0_LampOFF, 1=Cx1_LampON, 2=Cx2_flash, 3=Cx3_Invalid}, range raw 0..3, transfer-property=PENDING, to VCU  # EN: EPB Function Lamp CH: ¹¦ÄÜÖ¸Ê¾µÆ
          signal MessageCounter_5B_oIBS_Status2_oKAMA_FP_EPSChassis1_0303: start 51, 4 bit, big-endian, i-signal-type=PRIMITIVE, init-value=0, base-type=uint8, compu {identical}, range raw 0..15, transfer-property=PENDING, to VCU
          signal Checksum_5B_oIBS_Status2_oKAMA_FP_EPSChassis1_0303: start 63, 8 bit, big-endian, i-signal-type=PRIMITIVE, init-value=0, base-type=uint8, compu {identical}, range raw 0..255, transfer-property=PENDING, to VCU
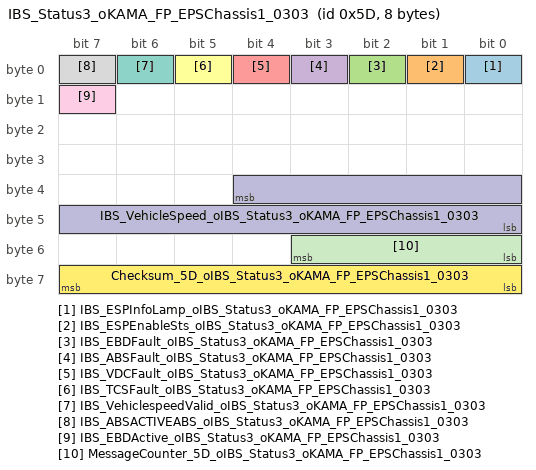
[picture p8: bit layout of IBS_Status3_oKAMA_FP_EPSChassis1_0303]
      frame IBS_Status3_oKAMA_FP_EPSChassis1_0303: id 0x5D, to VCU, frame-length=8, can-addressing-mode=STANDARD
        pdu IBS_Status3_oKAMA_FP_EPSChassis1_0303: length=8, minimum-delay=0, transmission-mode-false-timing=cyclic-timing={time-offset=0, time-period=0.02}, transmission-mode-true-timing=cyclic-timing={time-offset=0, time-period=0.02}, unused-bit-pattern=0
          signal IBS_ESPInfoLamp_oIBS_Status3_oKAMA_FP_EPSChassis1_0303: start 0, 1 bit, big-endian, i-signal-type=PRIMITIVE, init-value=0, base-type=boolean, compu {0=Cx0_NotActive, 1=Cx1_Active}, range raw 0..1, transfer-property=PENDING, to VCU  # EN:Info lamp - Indication that VDC/TCS(engine torque control or brake torque control) system currently performs a brake/engine intervention CH:ESC¹¤×÷Ê±£¬ÒÇ±í½ÓÊÕµ½´ËÐÅºÅ¿ªÊ¼ÉÁË¸
          signal IBS_ESPEnableSts_oIBS_Status3_oKAMA_FP_EPSChassis1_0303: start 1, 1 bit, big-endian, i-signal-type=PRIMITIVE, init-value=0, base-type=boolean, compu {0=Cx0_OFF, 1=Cx1_ON}, range raw 0..1, transfer-property=PENDING, to VCU  # EN:ESP function enabled/disabled status CH£ºESC¹¦ÄÜ¿ª¹ØÐÅºÅ
          signal IBS_EBDFault_oIBS_Status3_oKAMA_FP_EPSChassis1_0303: start 2, 1 bit, big-endian, i-signal-type=PRIMITIVE, init-value=0, base-type=boolean, compu {0=Cx0_Noerror, 1=Cx1_Error}, range raw 0..1, transfer-property=PENDING, to VCU
          signal IBS_ABSFault_oIBS_Status3_oKAMA_FP_EPSChassis1_0303: start 3, 1 bit, big-endian, i-signal-type=PRIMITIVE, init-value=0, base-type=boolean, compu {0=Cx0_Noerror, 1=Cx1_Error}, range raw 0..1, transfer-property=PENDING, to VCU
          signal IBS_VDCFault_oIBS_Status3_oKAMA_FP_EPSChassis1_0303: start 4, 1 bit, big-endian, i-signal-type=PRIMITIVE, init-value=0, base-type=boolean, compu {0=Cx0_Noerror, 1=Cx1_Error}, range raw 0..1, transfer-property=PENDING, to VCU  # EN:VDC status valid CH:VDC¹¦ÄÜ¹ÊÕÏ±êÖ¾Î»
          signal IBS_TCSFault_oIBS_Status3_oKAMA_FP_EPSChassis1_0303: start 5, 1 bit, big-endian, i-signal-type=PRIMITIVE, init-value=0, base-type=boolean, compu {0=Cx0_Noerror, 1=Cx1_Error}, range raw 0..1, transfer-property=PENDING, to VCU  # EN:TCS status valid CH:TCS¹¦ÄÜ¹ÊÕÏ±êÖ¾Î»
          signal IBS_VehiclespeedValid_oIBS_Status3_oKAMA_FP_EPSChassis1_0303: start 6, 1 bit, big-endian, i-signal-type=PRIMITIVE, init-value=0, base-type=boolean, compu {0=Cx0_valid, 1=Cx1_not_valid (not valid)}, range raw 0..1, transfer-property=PENDING, to VCU
          signal IBS_ABSACTIVEABS_oIBS_Status3_oKAMA_FP_EPSChassis1_0303: start 7, 1 bit, big-endian, i-signal-type=PRIMITIVE, init-value=0, base-type=boolean, compu {0=Cx0_NotActive, 1=Cx1_Active}, range raw 0..1, transfer-property=PENDING, to VCU  # EN:indicates ABS intervention active. CH:ABS¼¤»î±êÖ¾Î»£¬±íÊ¾ABS´¦ÓÚ¼¤»î×´Ì¬
          signal IBS_EBDActive_oIBS_Status3_oKAMA_FP_EPSChassis1_0303: start 15, 1 bit, big-endian, i-signal-type=PRIMITIVE, init-value=0, base-type=boolean, compu {0=Cx0_NotActive, 1=Cx1_Active}, range raw 0..1, transfer-property=PENDING, to VCU  # EN:indicates EBD intervention active. CH:EBD¼¤»î±êÖ¾Î»£¬±íÊ¾EBD´¦ÓÚ¼¤»î×´Ì¬
          signal IBS_VehicleSpeed_oIBS_Status3_oKAMA_FP_EPSChassis1_0303: start 36, 13 bit, big-endian, i-signal-type=PRIMITIVE, init-value=6400, base-type=uint16, compu {phys=raw*0.05625 for raw 0..6400; unit km/h}, range raw 0..6400, unit=km/h, transfer-property=PENDING, to VCU  # EN:Vehicle speed CH:Êä³ö³µËÙÐÅºÅ
          signal MessageCounter_5D_oIBS_Status3_oKAMA_FP_EPSChassis1_0303: start 51, 4 bit, big-endian, i-signal-type=PRIMITIVE, init-value=0, base-type=uint8, compu {identical}, range raw 0..15, transfer-property=PENDING, to VCU
          signal Checksum_5D_oIBS_Status3_oKAMA_FP_EPSChassis1_0303: start 63, 8 bit, big-endian, i-signal-type=PRIMITIVE, init-value=0, base-type=uint8, compu {identical}, range raw 0..255, transfer-property=PENDING, to VCU
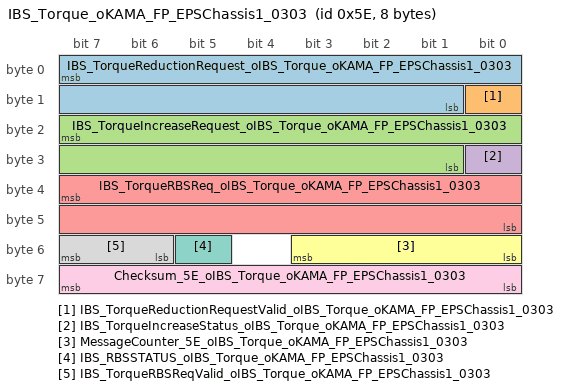
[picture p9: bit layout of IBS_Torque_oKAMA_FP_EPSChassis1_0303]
      frame IBS_Torque_oKAMA_FP_EPSChassis1_0303: id 0x5E, to VCU, frame-length=8, can-addressing-mode=STANDARD
        pdu IBS_Torque_oKAMA_FP_EPSChassis1_0303: length=8, minimum-delay=0, transmission-mode-false-timing=cyclic-timing={time-offset=0, time-period=0.02}, transmission-mode-true-timing=cyclic-timing={time-offset=0, time-period=0.02}, unused-bit-pattern=0
          signal IBS_TorqueReductionRequest_oIBS_Torque_oKAMA_FP_EPSChassis1_0303: start 7, 15 bit, big-endian, i-signal-type=PRIMITIVE, init-value=5400, base-type=uint16, compu {phys=raw-5400 for raw 0..17400; unit NM}, range raw 0..17400, unit=NM, transfer-property=PENDING, to VCU  # EN:engine torque fast reduction request CH:ESCÇëÇó·¢¶¯»ú¿ìËÙ½µÅ¤ÊýÖµ
          signal IBS_TorqueReductionRequestValid_oIBS_Torque_oKAMA_FP_EPSChassis1_0303: start 8, 1 bit, big-endian, i-signal-type=PRIMITIVE, init-value=0, base-type=boolean, compu {0=Cx0_NotActive, 1=Cx1_Active}, range raw 0..1, transfer-property=PENDING, to VCU  # EN£ºEngine torque reduction request status CH:ESCÇëÇó·¢¶¯»úÏìÓ¦½µÅ¤±êÖ¾Î»
          signal IBS_TorqueIncreaseRequest_oIBS_Torque_oKAMA_FP_EPSChassis1_0303: start 23, 15 bit, big-endian, i-signal-type=PRIMITIVE, init-value=5400, base-type=uint16, compu {phys=raw-5400 for raw 0..17400; unit NM}, range raw 0..17400, unit=NM, transfer-property=PENDING, to VCU  # EN:engine torque increase request CH:ESCÔöÅ¤ÇëÇó
          signal IBS_TorqueIncreaseStatus_oIBS_Torque_oKAMA_FP_EPSChassis1_0303: start 24, 1 bit, big-endian, i-signal-type=PRIMITIVE, init-value=0, base-type=boolean, compu {0=Cx0_NotActive, 1=Cx1_Active}, range raw 0..1, transfer-property=PENDING, to VCU  # EN£ºEngine torque increase request status CH:ESCÇëÇó·¢¶¯»úÏìÓ¦ÔöÅ¤±êÖ¾Î»
          signal IBS_TorqueRBSReq_oIBS_Torque_oKAMA_FP_EPSChassis1_0303: start 39, 16 bit, big-endian, i-signal-type=PRIMITIVE, init-value=32768, base-type=uint16, compu {phys=raw-32768 for raw 0..65535; unit Nm}, range raw 0..65535, unit=Nm, transfer-property=PENDING, to VCU  # EN:Motor torque demand CH:µç»ú×ª¾ØÐèÇó
          signal MessageCounter_5E_oIBS_Torque_oKAMA_FP_EPSChassis1_0303: start 51, 4 bit, big-endian, i-signal-type=PRIMITIVE, init-value=0, base-type=uint8, compu {identical}, range raw 0..15, transfer-property=PENDING, to VCU
          signal IBS_RBSSTATUS_oIBS_Torque_oKAMA_FP_EPSChassis1_0303: start 53, 1 bit, big-endian, i-signal-type=PRIMITIVE, init-value=0, base-type=boolean, compu {0=Cx0_NotActive, 1=Cx1_Active}, range raw 0..1, transfer-property=PENDING, to VCU  # EN:Energy recovery status CH:ÄÜÁ¿»ØÊÕ×´Ì¬±êÖ¾
          signal IBS_TorqueRBSReqValid_oIBS_Torque_oKAMA_FP_EPSChassis1_0303: start 55, 2 bit, big-endian, i-signal-type=PRIMITIVE, init-value=0, base-type=uint8, compu {0=Cx0_NotIntialized, 1=Cx1_Normal, 2=Cx2_Faulty}, range raw 0..3, transfer-property=PENDING, to VCU  # EN:Motor torque demand valid CH:µç»ú×ª¾ØÐèÇóÓÐÐ§×´Ì¬
          signal Checksum_5E_oIBS_Torque_oKAMA_FP_EPSChassis1_0303: start 63, 8 bit, big-endian, i-signal-type=PRIMITIVE, init-value=0, base-type=uint8, compu {identical}, range raw 0..255, transfer-property=PENDING, to VCU
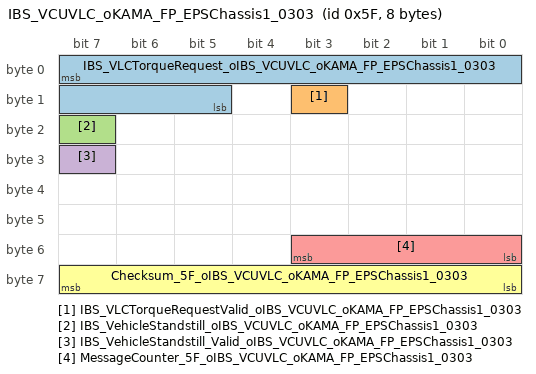
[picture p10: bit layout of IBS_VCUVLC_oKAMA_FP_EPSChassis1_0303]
      frame IBS_VCUVLC_oKAMA_FP_EPSChassis1_0303: id 0x5F, to VCU, frame-length=8, can-addressing-mode=STANDARD
        pdu IBS_VCUVLC_oKAMA_FP_EPSChassis1_0303: length=8, minimum-delay=0, transmission-mode-false-timing=cyclic-timing={time-offset=0, time-period=0.02}, transmission-mode-true-timing=cyclic-timing={time-offset=0, time-period=0.02}, unused-bit-pattern=0
          signal IBS_VLCTorqueRequest_oIBS_VCUVLC_oKAMA_FP_EPSChassis1_0303: start 7, 11 bit, big-endian, i-signal-type=PRIMITIVE, init-value=1024, base-type=uint16, compu {phys=raw-1024 for raw 0..2047}, range raw 0..2047, transfer-property=PENDING, to VCU  # VLC Torque Request Value
          signal IBS_VLCTorqueRequestValid_oIBS_VCUVLC_oKAMA_FP_EPSChassis1_0303: start 11, 1 bit, big-endian, i-signal-type=PRIMITIVE, init-value=0, base-type=boolean, compu {0=Cx0_NotActive, 1=Cx1_Active}, range raw 0..1, transfer-property=PENDING, to VCU  # VLC Torque Request active
          signal IBS_VehicleStandstill_oIBS_VCUVLC_oKAMA_FP_EPSChassis1_0303: start 23, 1 bit, big-endian, i-signal-type=PRIMITIVE, init-value=0, base-type=boolean, compu {0=Cx0_NOT_STANDSTILL, 1=Cx1_STANDSTILL}, range raw 0..1, transfer-property=PENDING, to VCU
          signal IBS_VehicleStandstill_Valid_oIBS_VCUVLC_oKAMA_FP_EPSChassis1_0303: start 31, 1 bit, big-endian, i-signal-type=PRIMITIVE, init-value=0, base-type=boolean, compu {0=Cx0_invalid, 1=Cx1_valid}, range raw 0..1, transfer-property=PENDING, to VCU
          signal MessageCounter_5F_oIBS_VCUVLC_oKAMA_FP_EPSChassis1_0303: start 51, 4 bit, big-endian, i-signal-type=PRIMITIVE, init-value=0, base-type=uint8, compu {identical}, range raw 0..15, transfer-property=PENDING, to VCU
          signal Checksum_5F_oIBS_VCUVLC_oKAMA_FP_EPSChassis1_0303: start 63, 8 bit, big-endian, i-signal-type=PRIMITIVE, init-value=0, base-type=uint8, compu {identical}, range raw 0..255, transfer-property=PENDING, to VCU
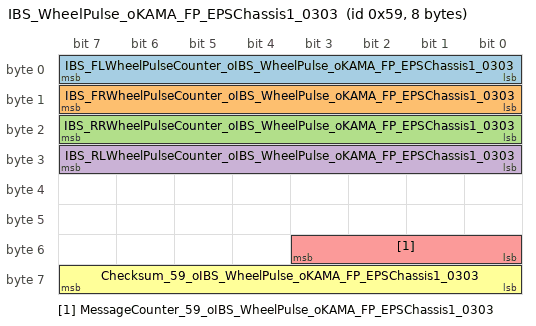
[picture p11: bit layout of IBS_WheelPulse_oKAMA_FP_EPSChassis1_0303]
      frame IBS_WheelPulse_oKAMA_FP_EPSChassis1_0303: id 0x59, to VCU, frame-length=8, can-addressing-mode=STANDARD
        pdu IBS_WheelPulse_oKAMA_FP_EPSChassis1_0303: length=8, minimum-delay=0, transmission-mode-false-timing=cyclic-timing={time-offset=0, time-period=0.02}, transmission-mode-true-timing=cyclic-timing={time-offset=0, time-period=0.02}, unused-bit-pattern=0
          signal IBS_FLWheelPulseCounter_oIBS_WheelPulse_oKAMA_FP_EPSChassis1_0303: start 7, 8 bit, big-endian, i-signal-type=PRIMITIVE, init-value=0, base-type=uint8, compu {identical}, range raw 0..255, transfer-property=PENDING, to VCU  # EN:Front left wheel speed pulse CH£º×óÇ°ÂÖÂö³å¼ÆÊý
          signal IBS_FRWheelPulseCounter_oIBS_WheelPulse_oKAMA_FP_EPSChassis1_0303: start 15, 8 bit, big-endian, i-signal-type=PRIMITIVE, init-value=0, base-type=uint8, compu {identical}, range raw 0..255, transfer-property=PENDING, to VCU  # EN:Front right wheel speed pulse CH£ºÓÒÇ°ÂÖÂö³å¼ÆÊý
          signal IBS_RRWheelPulseCounter_oIBS_WheelPulse_oKAMA_FP_EPSChassis1_0303: start 23, 8 bit, big-endian, i-signal-type=PRIMITIVE, init-value=0, base-type=uint8, compu {identical}, range raw 0..255, transfer-property=PENDING, to VCU  # EN:Rear right wheel speed pulse CH£ºÓÒºóÂÖÂö³å¼ÆÊý
          signal IBS_RLWheelPulseCounter_oIBS_WheelPulse_oKAMA_FP_EPSChassis1_0303: start 31, 8 bit, big-endian, i-signal-type=PRIMITIVE, init-value=0, base-type=uint8, compu {identical}, range raw 0..255, transfer-property=PENDING, to VCU  # EN:Rear left wheel speed pulse CH£º×óºóÂÖÂö³å¼ÆÊý
          signal MessageCounter_59_oIBS_WheelPulse_oKAMA_FP_EPSChassis1_0303: start 51, 4 bit, big-endian, i-signal-type=PRIMITIVE, init-value=0, base-type=uint8, compu {identical}, range raw 0..15, transfer-property=PENDING, to VCU
          signal Checksum_59_oIBS_WheelPulse_oKAMA_FP_EPSChassis1_0303: start 63, 8 bit, big-endian, i-signal-type=PRIMITIVE, init-value=0, base-type=uint8, compu {identical}, range raw 0..255, transfer-property=PENDING, to VCU
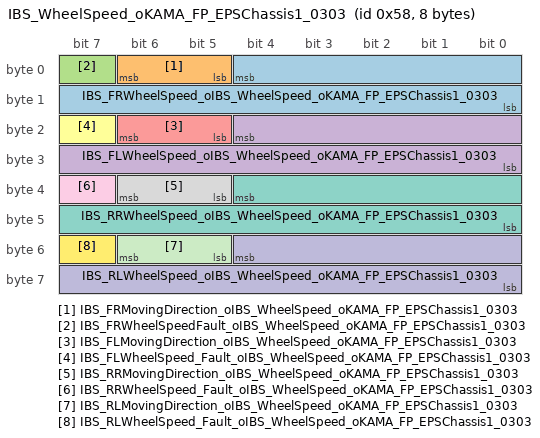
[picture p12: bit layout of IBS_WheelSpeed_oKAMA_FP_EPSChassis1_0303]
      frame IBS_WheelSpeed_oKAMA_FP_EPSChassis1_0303: id 0x58, to VCU, frame-length=8, can-addressing-mode=STANDARD
        pdu IBS_WheelSpeed_oKAMA_FP_EPSChassis1_0303: length=8, minimum-delay=0, transmission-mode-false-timing=cyclic-timing={time-offset=0, time-period=0.02}, transmission-mode-true-timing=cyclic-timing={time-offset=0, time-period=0.02}, unused-bit-pattern=0
          signal IBS_FRWheelSpeed_oIBS_WheelSpeed_oKAMA_FP_EPSChassis1_0303: start 4, 13 bit, big-endian, i-signal-type=PRIMITIVE, init-value=0, base-type=uint16, compu {phys=raw*0.05625 for raw 0..6400; unit km/h}, range raw 0..6400, unit=km/h, transfer-property=PENDING, to VCU  # EN: Front right wheel speed CH:ÓÒÇ°ÂÖÂÖËÙÐÅºÅ
          signal IBS_FRMovingDirection_oIBS_WheelSpeed_oKAMA_FP_EPSChassis1_0303: start 6, 2 bit, big-endian, i-signal-type=PRIMITIVE, init-value=0, base-type=uint8, compu {0=Cx0_Standstill, 1=Cx1_Forward, 2=Cx2_Backward}, range raw 0..3, transfer-property=PENDING, to VCU
          signal IBS_FRWheelSpeedFault_oIBS_WheelSpeed_oKAMA_FP_EPSChassis1_0303: start 7, 1 bit, big-endian, i-signal-type=PRIMITIVE, init-value=0, base-type=boolean, compu {0=Cx0_No_error (No error), 1=Cx1_Error_ (Error;)}, range raw 0..1, transfer-property=PENDING, to VCU  # EN:Front right wheel speed signal valid CH:ÓÒÇ°ÂÖÂÖËÙÓÐÐ§ÐÅºÅ
          signal IBS_FLWheelSpeed_oIBS_WheelSpeed_oKAMA_FP_EPSChassis1_0303: start 20, 13 bit, big-endian, i-signal-type=PRIMITIVE, init-value=0, base-type=uint16, compu {phys=raw*0.05625 for raw 0..6400; unit km/h}, range raw 0..6400, unit=km/h, transfer-property=PENDING, to VCU  # EN:Front left wheel speed CH:×óÇ°ÂÖÂÖËÙÐÅºÅ
          signal IBS_FLMovingDirection_oIBS_WheelSpeed_oKAMA_FP_EPSChassis1_0303: start 22, 2 bit, big-endian, i-signal-type=PRIMITIVE, init-value=0, base-type=uint8, compu {0=Cx0_Standstill, 1=Cx1_Forward, 2=Cx2_Backward}, range raw 0..3, transfer-property=PENDING, to VCU
          signal IBS_FLWheelSpeed_Fault_oIBS_WheelSpeed_oKAMA_FP_EPSChassis1_0303: start 23, 1 bit, big-endian, i-signal-type=PRIMITIVE, init-value=0, base-type=boolean, compu {0=Cx0_No_error (No error), 1=Cx1_Error_ (Error;)}, range raw 0..1, transfer-property=PENDING, to VCU  # EN:Front left wheel speed signal valid CH:×óÇ°ÂÖÂÖËÙÓÐÐ§ÐÅºÅ
          signal IBS_RRWheelSpeed_oIBS_WheelSpeed_oKAMA_FP_EPSChassis1_0303: start 36, 13 bit, big-endian, i-signal-type=PRIMITIVE, init-value=0, base-type=uint16, compu {phys=raw*0.05625 for raw 0..6400; unit km/h}, range raw 0..6400, unit=km/h, transfer-property=PENDING, to VCU  # EN:Rear right wheel speed CH:ÓÒºóÂÖÂÖËÙÐÅºÅ
          signal IBS_RRMovingDirection_oIBS_WheelSpeed_oKAMA_FP_EPSChassis1_0303: start 38, 2 bit, big-endian, i-signal-type=PRIMITIVE, init-value=0, base-type=uint8, compu {0=Cx0_Standstill, 1=Cx1_Forward, 2=Cx2_Backward}, range raw 0..3, transfer-property=PENDING, to VCU
          signal IBS_RRWheelSpeed_Fault_oIBS_WheelSpeed_oKAMA_FP_EPSChassis1_0303: start 39, 1 bit, big-endian, i-signal-type=PRIMITIVE, init-value=0, base-type=boolean, compu {0=Cx0_No_error (No error), 1=Cx1_Error_ (Error;)}, range raw 0..1, transfer-property=PENDING, to VCU  # EN:Rear right wheel speed signal valid CH:ÓÒºóÂÖÂÖËÙÓÐÐ§ÐÅºÅ
          signal IBS_RLWheelSpeed_oIBS_WheelSpeed_oKAMA_FP_EPSChassis1_0303: start 52, 13 bit, big-endian, i-signal-type=PRIMITIVE, init-value=0, base-type=uint16, compu {phys=raw*0.05625 for raw 0..6400; unit km/h}, range raw 0..6400, unit=km/h, transfer-property=PENDING, to VCU  # EN:Rear left wheel speed CH:×óºóÂÖÂÖËÙÐÅºÅ
          signal IBS_RLMovingDirection_oIBS_WheelSpeed_oKAMA_FP_EPSChassis1_0303: start 54, 2 bit, big-endian, i-signal-type=PRIMITIVE, init-value=0, base-type=uint8, compu {0=Cx0_Standstill, 1=Cx1_Forward, 2=Cx2_Backward}, range raw 0..3, transfer-property=PENDING, to VCU
          signal IBS_RLWheelSpeed_Fault_oIBS_WheelSpeed_oKAMA_FP_EPSChassis1_0303: start 55, 1 bit, big-endian, i-signal-type=PRIMITIVE, init-value=0, base-type=boolean, compu {0=Cx0_No_error (No error), 1=Cx1_Error_ (Error;)}, range raw 0..1, transfer-property=PENDING, to VCU  # EN:Rear left wheel speed signal valid CH:×óºóÂÖÂÖËÙÓÐÐ§ÐÅºÅ
      frame IBS1_acceleration_oKAMA_FP_EPSChassis1_0303: id 0x5C, to VCU, frame-length=8, can-addressing-mode=STANDARD
        pdu IBS1_acceleration_oKAMA_FP_EPSChassis1_0303: length=8, minimum-delay=0, transmission-mode-false-timing=cyclic-timing={time-offset=0, time-period=0.02}, transmission-mode-true-timing=cyclic-timing={time-offset=0, time-period=0.02}, unused-bit-pattern=0
          signal IBS_ESCYawRate_oIBS1_acceleration_oKAMA_FP_EPSChassis1_0303: start 7, 16 bit, big-endian, i-signal-type=PRIMITIVE, init-value=32768, base-type=uint16, compu {phys=raw*0.005-163.84 for raw 0..65534; unit ¡ã/s}, range raw 0..65534, unit=¡ã/s, transfer-property=PENDING, to VCU  # EN:yaw rate CH:ÓÉESC×ª·¢YRSºá°Ú½ÇËÙ¶ÈÐÅºÅ
          signal IBS_ESCLateralAccle_oIBS1_acceleration_oKAMA_FP_EPSChassis1_0303: start 23, 16 bit, big-endian, i-signal-type=PRIMITIVE, init-value=32784.9293563579, base-type=uint16, compu {phys=raw*0.0001274-4.1768 for raw 0..65535; unit g/digit}, range raw 0..65535, unit=g/digit, transfer-property=PENDING, to VCU  # EN:Lateral acceleration CH:ÓÉESC×ª·¢YRS²àÏò¼ÓËÙ¶ÈÐÅºÅ
          signal IBS_ESCLongitudinalAccle_oIBS1_acceleration_oKAMA_FP_EPSChassis1_0303: start 39, 16 bit, big-endian, i-signal-type=PRIMITIVE, init-value=32784.9293563579, base-type=uint16, compu {phys=raw*0.0001274-4.1768 for raw 0..65535; unit g/digit}, range raw 0..65535, unit=g/digit, transfer-property=PENDING, to VCU  # EN:Longitudinal acceleration CH:ÓÉESC×ª·¢YRS×ÝÏò¼ÓËÙ¶ÈÐÅºÅ
          signal MessageCounter_5C_oIBS1_acceleration_oKAMA_FP_EPSChassis1_0303: start 51, 4 bit, big-endian, i-signal-type=PRIMITIVE, init-value=0, base-type=uint8, compu {identical}, range raw 0..15, transfer-property=PENDING, to VCU
          signal Checksum_5C_oIBS1_acceleration_oKAMA_FP_EPSChassis1_0303: start 63, 8 bit, big-endian, i-signal-type=PRIMITIVE, init-value=0, base-type=uint8, compu {identical}, range raw 0..255, transfer-property=PENDING, to VCU
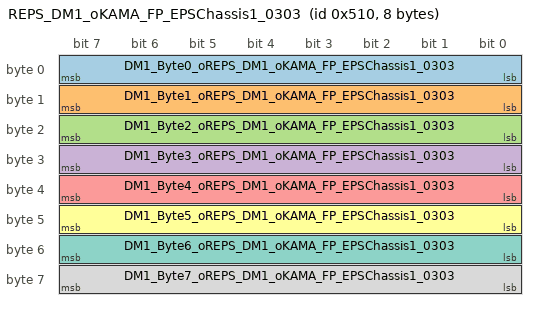
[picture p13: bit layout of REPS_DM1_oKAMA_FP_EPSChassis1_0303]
      frame REPS_DM1_oKAMA_FP_EPSChassis1_0303: id 0x510, to VCU, frame-length=8, can-addressing-mode=STANDARD
        pdu REPS_DM1_oKAMA_FP_EPSChassis1_0303: length=8, minimum-delay=0, transmission-mode-false-timing=cyclic-timing={time-offset=0, time-period=0.1}, transmission-mode-true-timing=cyclic-timing={time-offset=0, time-period=0.1}, unused-bit-pattern=0
          signal DM1_Byte0_oREPS_DM1_oKAMA_FP_EPSChassis1_0303: start 7, 8 bit, big-endian, i-signal-type=PRIMITIVE, init-value=0, base-type=uint8, compu {identical}, range raw 0..255, transfer-property=PENDING, to VCU
          signal DM1_Byte1_oREPS_DM1_oKAMA_FP_EPSChassis1_0303: start 15, 8 bit, big-endian, i-signal-type=PRIMITIVE, init-value=0, base-type=uint8, compu {identical}, range raw 0..255, transfer-property=PENDING, to VCU
          signal DM1_Byte2_oREPS_DM1_oKAMA_FP_EPSChassis1_0303: start 23, 8 bit, big-endian, i-signal-type=PRIMITIVE, init-value=0, base-type=uint8, compu {identical}, range raw 0..255, transfer-property=PENDING, to VCU
          signal DM1_Byte3_oREPS_DM1_oKAMA_FP_EPSChassis1_0303: start 31, 8 bit, big-endian, i-signal-type=PRIMITIVE, init-value=0, base-type=uint8, compu {identical}, range raw 0..255, transfer-property=PENDING, to VCU
          signal DM1_Byte4_oREPS_DM1_oKAMA_FP_EPSChassis1_0303: start 39, 8 bit, big-endian, i-signal-type=PRIMITIVE, init-value=0, base-type=uint8, compu {identical}, range raw 0..255, transfer-property=PENDING, to VCU
          signal DM1_Byte5_oREPS_DM1_oKAMA_FP_EPSChassis1_0303: start 47, 8 bit, big-endian, i-signal-type=PRIMITIVE, init-value=0, base-type=uint8, compu {identical}, range raw 0..255, transfer-property=PENDING, to VCU
          signal DM1_Byte6_oREPS_DM1_oKAMA_FP_EPSChassis1_0303: start 55, 8 bit, big-endian, i-signal-type=PRIMITIVE, init-value=0, base-type=uint8, compu {identical}, range raw 0..255, transfer-property=PENDING, to VCU
          signal DM1_Byte7_oREPS_DM1_oKAMA_FP_EPSChassis1_0303: start 63, 8 bit, big-endian, i-signal-type=PRIMITIVE, init-value=0, base-type=uint8, compu {identical}, range raw 0..255, transfer-property=PENDING, to VCU
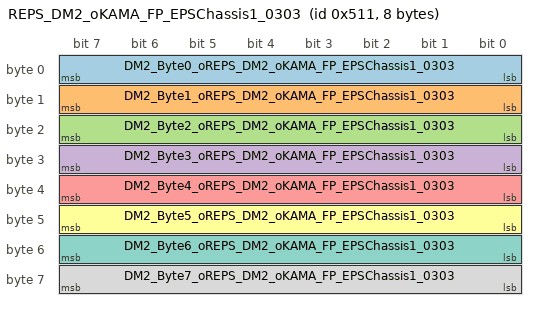
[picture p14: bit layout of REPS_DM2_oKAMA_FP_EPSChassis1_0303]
      frame REPS_DM2_oKAMA_FP_EPSChassis1_0303: id 0x511, to VCU, frame-length=8, can-addressing-mode=STANDARD
        pdu REPS_DM2_oKAMA_FP_EPSChassis1_0303: length=8, minimum-delay=0, transmission-mode-false-timing=cyclic-timing={time-offset=0, time-period=0.1}, transmission-mode-true-timing=cyclic-timing={time-offset=0, time-period=0.1}, unused-bit-pattern=0
          signal DM2_Byte0_oREPS_DM2_oKAMA_FP_EPSChassis1_0303: start 7, 8 bit, big-endian, i-signal-type=PRIMITIVE, init-value=0, base-type=uint8, compu {identical}, range raw 0..255, transfer-property=PENDING, to VCU
          signal DM2_Byte1_oREPS_DM2_oKAMA_FP_EPSChassis1_0303: start 15, 8 bit, big-endian, i-signal-type=PRIMITIVE, init-value=0, base-type=uint8, compu {identical}, range raw 0..255, transfer-property=PENDING, to VCU
          signal DM2_Byte2_oREPS_DM2_oKAMA_FP_EPSChassis1_0303: start 23, 8 bit, big-endian, i-signal-type=PRIMITIVE, init-value=0, base-type=uint8, compu {identical}, range raw 0..255, transfer-property=PENDING, to VCU
          signal DM2_Byte3_oREPS_DM2_oKAMA_FP_EPSChassis1_0303: start 31, 8 bit, big-endian, i-signal-type=PRIMITIVE, init-value=0, base-type=uint8, compu {identical}, range raw 0..255, transfer-property=PENDING, to VCU
          signal DM2_Byte4_oREPS_DM2_oKAMA_FP_EPSChassis1_0303: start 39, 8 bit, big-endian, i-signal-type=PRIMITIVE, init-value=0, base-type=uint8, compu {identical}, range raw 0..255, transfer-property=PENDING, to VCU
          signal DM2_Byte5_oREPS_DM2_oKAMA_FP_EPSChassis1_0303: start 47, 8 bit, big-endian, i-signal-type=PRIMITIVE, init-value=0, base-type=uint8, compu {identical}, range raw 0..255, transfer-property=PENDING, to VCU
          signal DM2_Byte6_oREPS_DM2_oKAMA_FP_EPSChassis1_0303: start 55, 8 bit, big-endian, i-signal-type=PRIMITIVE, init-value=0, base-type=uint8, compu {identical}, range raw 0..255, transfer-property=PENDING, to VCU
          signal DM2_Byte7_oREPS_DM2_oKAMA_FP_EPSChassis1_0303: start 63, 8 bit, big-endian, i-signal-type=PRIMITIVE, init-value=0, base-type=uint8, compu {identical}, range raw 0..255, transfer-property=PENDING, to VCU
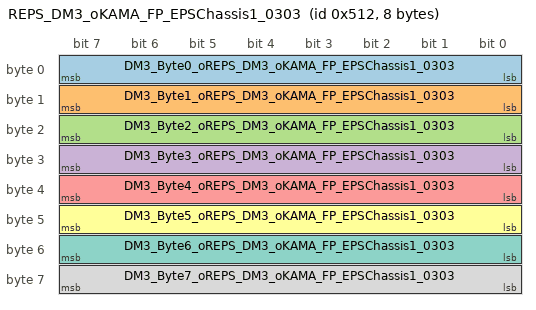
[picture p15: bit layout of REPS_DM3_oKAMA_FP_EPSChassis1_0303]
      frame REPS_DM3_oKAMA_FP_EPSChassis1_0303: id 0x512, to VCU, frame-length=8, can-addressing-mode=STANDARD
        pdu REPS_DM3_oKAMA_FP_EPSChassis1_0303: length=8, minimum-delay=0, transmission-mode-false-timing=cyclic-timing={time-offset=0, time-period=0.1}, transmission-mode-true-timing=cyclic-timing={time-offset=0, time-period=0.1}, unused-bit-pattern=0
          signal DM3_Byte0_oREPS_DM3_oKAMA_FP_EPSChassis1_0303: start 7, 8 bit, big-endian, i-signal-type=PRIMITIVE, init-value=0, base-type=uint8, compu {identical}, range raw 0..255, transfer-property=PENDING, to VCU
          signal DM3_Byte1_oREPS_DM3_oKAMA_FP_EPSChassis1_0303: start 15, 8 bit, big-endian, i-signal-type=PRIMITIVE, init-value=0, base-type=uint8, compu {identical}, range raw 0..255, transfer-property=PENDING, to VCU
          signal DM3_Byte2_oREPS_DM3_oKAMA_FP_EPSChassis1_0303: start 23, 8 bit, big-endian, i-signal-type=PRIMITIVE, init-value=0, base-type=uint8, compu {identical}, range raw 0..255, transfer-property=PENDING, to VCU
          signal DM3_Byte3_oREPS_DM3_oKAMA_FP_EPSChassis1_0303: start 31, 8 bit, big-endian, i-signal-type=PRIMITIVE, init-value=0, base-type=uint8, compu {identical}, range raw 0..255, transfer-property=PENDING, to VCU
          signal DM3_Byte4_oREPS_DM3_oKAMA_FP_EPSChassis1_0303: start 39, 8 bit, big-endian, i-signal-type=PRIMITIVE, init-value=0, base-type=uint8, compu {identical}, range raw 0..255, transfer-property=PENDING, to VCU
          signal DM3_Byte5_oREPS_DM3_oKAMA_FP_EPSChassis1_0303: start 47, 8 bit, big-endian, i-signal-type=PRIMITIVE, init-value=0, base-type=uint8, compu {identical}, range raw 0..255, transfer-property=PENDING, to VCU
          signal DM3_Byte6_oREPS_DM3_oKAMA_FP_EPSChassis1_0303: start 55, 8 bit, big-endian, i-signal-type=PRIMITIVE, init-value=0, base-type=uint8, compu {identical}, range raw 0..255, transfer-property=PENDING, to VCU
          signal DM3_Byte7_oREPS_DM3_oKAMA_FP_EPSChassis1_0303: start 63, 8 bit, big-endian, i-signal-type=PRIMITIVE, init-value=0, base-type=uint8, compu {identical}, range raw 0..255, transfer-property=PENDING, to VCU
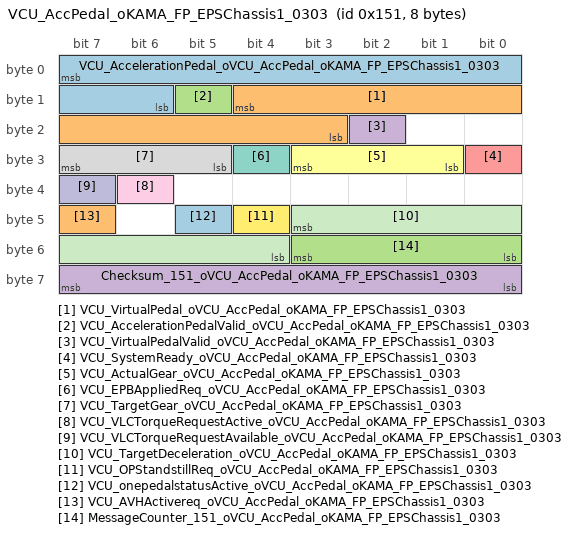
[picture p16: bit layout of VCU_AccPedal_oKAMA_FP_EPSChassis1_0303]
      frame VCU_AccPedal_oKAMA_FP_EPSChassis1_0303: id 0x151, from VCU, frame-length=8, can-addressing-mode=STANDARD
        pdu VCU_AccPedal_oKAMA_FP_EPSChassis1_0303: length=8, minimum-delay=0, transmission-mode-false-timing=cyclic-timing={time-offset=0, time-period=0.02}, transmission-mode-true-timing=cyclic-timing={time-offset=0, time-period=0.02}, unused-bit-pattern=0
          signal VCU_AccelerationPedal_oVCU_AccPedal_oKAMA_FP_EPSChassis1_0303: start 7, 10 bit, big-endian, i-signal-type=PRIMITIVE, init-value=0, base-type=uint16, compu {phys=raw*0.1 for raw 0..1000; unit %}, range raw 0..1000, unit=%, transfer-property=PENDING
          signal VCU_VirtualPedal_oVCU_AccPedal_oKAMA_FP_EPSChassis1_0303: start 12, 10 bit, big-endian, i-signal-type=PRIMITIVE, init-value=0, base-type=uint16, compu {phys=raw*0.1 for raw 0..1000; unit %}, range raw 0..1000, unit=%, transfer-property=PENDING
          signal VCU_AccelerationPedalValid_oVCU_AccPedal_oKAMA_FP_EPSChassis1_0303: start 13, 1 bit, big-endian, i-signal-type=PRIMITIVE, init-value=0, base-type=boolean, compu {0=Cx0_invalid, 1=Cx1_valid}, range raw 0..1, transfer-property=PENDING
          signal VCU_VirtualPedalValid_oVCU_AccPedal_oKAMA_FP_EPSChassis1_0303: start 18, 1 bit, big-endian, i-signal-type=PRIMITIVE, init-value=0, base-type=boolean, compu {0=Cx0_invalid, 1=Cx1_valid}, range raw 0..1, transfer-property=PENDING
          signal VCU_SystemReady_oVCU_AccPedal_oKAMA_FP_EPSChassis1_0303: start 24, 1 bit, big-endian, i-signal-type=PRIMITIVE, init-value=0, base-type=boolean, compu {0=Cx0_Not_Ready (Not Ready), 1=Cx1_Ready}, range raw 0..1, transfer-property=PENDING
          signal VCU_ActualGear_oVCU_AccPedal_oKAMA_FP_EPSChassis1_0303: start 27, 3 bit, big-endian, i-signal-type=PRIMITIVE, init-value=0, base-type=uint8, compu {0=Cx0_reserve, 1=Cx1_P, 2=Cx2_N, 3=Cx3_R, 4=Cx4_D}, range raw 0..7, transfer-property=PENDING
          signal VCU_EPBAppliedReq_oVCU_AccPedal_oKAMA_FP_EPSChassis1_0303: start 28, 1 bit, big-endian, i-signal-type=PRIMITIVE, init-value=0, base-type=boolean, compu {0=Cx0_Not_Request (Not Request), 1=Cx1_Request}, range raw 0..1, transfer-property=PENDING
          signal VCU_TargetGear_oVCU_AccPedal_oKAMA_FP_EPSChassis1_0303: start 31, 3 bit, big-endian, i-signal-type=PRIMITIVE, init-value=0, base-type=uint8, compu {0=Cx0_reserve, 1=Cx1_P, 2=Cx2_N, 3=Cx3_R, 4=Cx4_D}, range raw 0..7, transfer-property=PENDING
          signal VCU_VLCTorqueRequestActive_oVCU_AccPedal_oKAMA_FP_EPSChassis1_0303: start 38, 1 bit, big-endian, i-signal-type=PRIMITIVE, init-value=0, base-type=boolean, compu {0=Cx0_Not_Active (Not Active), 1=Cx1_Active}, range raw 0..1, transfer-property=PENDING  # VCUÏìÓ¦VLCÅ¤¾ØÇëÇó¹¦ÄÜÊÇ·ñ¼¤»î
          signal VCU_VLCTorqueRequestAvailable_oVCU_AccPedal_oKAMA_FP_EPSChassis1_0303: start 39, 1 bit, big-endian, i-signal-type=PRIMITIVE, init-value=0, base-type=boolean, compu {0=Cx0_Not_Available (Not Available), 1=Cx1_Availabl}, range raw 0..1, transfer-property=PENDING  # VCUÏìÓ¦VLCÅ¤¾ØÇëÇóÊÇ·ñ¿ÉÓÃ
          signal VCU_TargetDeceleration_oVCU_AccPedal_oKAMA_FP_EPSChassis1_0303: start 43, 8 bit, big-endian, i-signal-type=PRIMITIVE, init-value=140, base-type=uint8, compu {phys=raw*0.05-7 for raw 0..255; unit m/s^2}, range raw 0..255, unit=m/s^2, transfer-property=PENDING
          signal VCU_OPStandstillReq_oVCU_AccPedal_oKAMA_FP_EPSChassis1_0303: start 44, 1 bit, big-endian, i-signal-type=PRIMITIVE, init-value=0, base-type=boolean, compu {0=Cx0_NO_DEMAND, 1=Cx1_DEMAND}, range raw 0..1, transfer-property=PENDING
          signal VCU_onepedalstatusActive_oVCU_AccPedal_oKAMA_FP_EPSChassis1_0303: start 45, 1 bit, big-endian, i-signal-type=PRIMITIVE, init-value=0, base-type=boolean, compu {0=Cx0_NotActive, 1=Cx1_Active}, range raw 0..1, transfer-property=PENDING
          signal VCU_AVHActivereq_oVCU_AccPedal_oKAMA_FP_EPSChassis1_0303: start 47, 1 bit, big-endian, i-signal-type=PRIMITIVE, init-value=0, base-type=boolean, compu {0=Cx0_NO_DEMAND, 1=Cx1_DEMAND}, range raw 0..1, transfer-property=PENDING
          signal MessageCounter_151_oVCU_AccPedal_oKAMA_FP_EPSChassis1_0303: start 51, 4 bit, big-endian, i-signal-type=PRIMITIVE, init-value=0, base-type=uint8, compu {identical}, range raw 0..7, transfer-property=PENDING
          signal Checksum_151_oVCU_AccPedal_oKAMA_FP_EPSChassis1_0303: start 63, 8 bit, big-endian, i-signal-type=PRIMITIVE, init-value=0, base-type=uint8, compu {identical}, range raw 0..255, transfer-property=PENDING
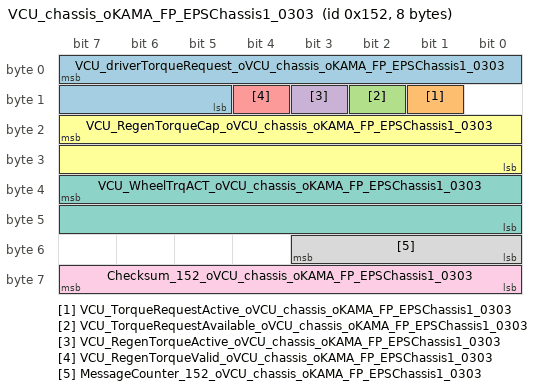
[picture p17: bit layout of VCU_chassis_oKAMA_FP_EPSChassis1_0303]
      frame VCU_chassis_oKAMA_FP_EPSChassis1_0303: id 0x152, from VCU, frame-length=8, can-addressing-mode=STANDARD
        pdu VCU_chassis_oKAMA_FP_EPSChassis1_0303: length=8, minimum-delay=0, transmission-mode-false-timing=cyclic-timing={time-offset=0, time-period=0.02}, transmission-mode-true-timing=cyclic-timing={time-offset=0, time-period=0.02}, unused-bit-pattern=0
          signal VCU_driverTorqueRequest_oVCU_chassis_oKAMA_FP_EPSChassis1_0303: start 7, 11 bit, big-endian, i-signal-type=PRIMITIVE, init-value=1023, base-type=uint16, compu {phys=raw-1023 for raw 0..2045; unit Nm}, range raw 0..2045, unit=Nm, transfer-property=PENDING  # ¼ÝÊ»Ô±ÐèÇóÅ¤¾Ø
          signal VCU_TorqueRequestActive_oVCU_chassis_oKAMA_FP_EPSChassis1_0303: start 9, 1 bit, big-endian, i-signal-type=PRIMITIVE, init-value=0, base-type=boolean, compu {0=Cx0_Not_Active (Not Active), 1=Cx1_Active}, range raw 0..1, transfer-property=PENDING  # VCUÏìÓ¦Íâ²¿Å¤¾ØÇëÇó¹¦ÄÜÊÇ·ñ¼¤»î
          signal VCU_TorqueRequestAvailable_oVCU_chassis_oKAMA_FP_EPSChassis1_0303: start 10, 1 bit, big-endian, i-signal-type=PRIMITIVE, init-value=0, base-type=boolean, compu {0=Cx0_Not_Available (Not Available), 1=Cx1_Available}, range raw 0..1, transfer-property=PENDING  # VCUÏìÓ¦Íâ²¿Å¤¾ØÇëÇóÊÇ·ñ¿ÉÓÃ
          signal VCU_RegenTorqueActive_oVCU_chassis_oKAMA_FP_EPSChassis1_0303: start 11, 1 bit, big-endian, i-signal-type=PRIMITIVE, init-value=0, base-type=boolean, compu {0=Cx0_Not_Active (Not Active), 1=Cx1_Active}, range raw 0..1, transfer-property=PENDING  # µç»ú×î´óÖÆ¶¯»ØÊÕÅ¤¾Ø×´Ì¬
          signal VCU_RegenTorqueValid_oVCU_chassis_oKAMA_FP_EPSChassis1_0303: start 12, 1 bit, big-endian, i-signal-type=PRIMITIVE, init-value=0, base-type=boolean, compu {0=Cx0_invalid, 1=Cx1_valid}, range raw 0..1, transfer-property=PENDING  # µç»ú×î´óÖÆ¶¯»ØÊÕÅ¤¾ØÓÐÐ§ÐÔ
          signal VCU_RegenTorqueCap_oVCU_chassis_oKAMA_FP_EPSChassis1_0303: start 23, 16 bit, big-endian, i-signal-type=PRIMITIVE, init-value=20000, base-type=uint16, compu {phys=raw-20000 for raw 0..40000; unit Nm}, range raw 0..40000, unit=Nm, transfer-property=PENDING  # µç»ú×î´óÖÆ¶¯»ØÊÕÅ¤¾Ø
          signal VCU_WheelTrqACT_oVCU_chassis_oKAMA_FP_EPSChassis1_0303: start 39, 16 bit, big-endian, i-signal-type=PRIMITIVE, init-value=20000, base-type=uint16, compu {phys=raw-20000 for raw 0..40000; unit Nm}, range raw 0..40000, unit=Nm, transfer-property=PENDING  # Êµ¼Êµç»úÅ¤¾Ø-ÂÖ¶Ë
          signal MessageCounter_152_oVCU_chassis_oKAMA_FP_EPSChassis1_0303: start 51, 4 bit, big-endian, i-signal-type=PRIMITIVE, init-value=0, base-type=uint8, compu {identical}, range raw 0..7, transfer-property=PENDING  # AliveCounter_xxx
          signal Checksum_152_oVCU_chassis_oKAMA_FP_EPSChassis1_0303: start 63, 8 bit, big-endian, i-signal-type=PRIMITIVE, init-value=0, base-type=uint8, compu {identical}, range raw 0..255, transfer-property=PENDING  # CRC-XXX
      frame VCU_HMIsignals_oKAMA_FP_EPSChassis1_0303: id 0x27B, from VCU, frame-length=8, can-addressing-mode=STANDARD
        pdu VCU_HMIsignals_oKAMA_FP_EPSChassis1_0303: length=8, minimum-delay=0, transmission-mode-false-timing=cyclic-timing={time-offset=0, time-period=0.2}, transmission-mode-true-timing=cyclic-timing={time-offset=0, time-period=0.2}, unused-bit-pattern=0
          signal VCU_HVILError_oVCU_HMIsignals_oKAMA_FP_EPSChassis1_0303: start 0, 1 bit, big-endian, i-signal-type=PRIMITIVE, init-value=0, base-type=boolean, compu {0=Cx0_False_ (False;), 1=Cx1_True}, range raw 0..1, transfer-property=PENDING  # HVIL error (Interlock monitoring device): required via GB/T 19836
          signal VCU_HVBatOvrTemp_oVCU_HMIsignals_oKAMA_FP_EPSChassis1_0303: start 1, 1 bit, big-endian, i-signal-type=PRIMITIVE, init-value=0, base-type=boolean, compu {0=Cx0_False_ (False;), 1=Cx1_True}, range raw 0..1, transfer-property=PENDING
          signal VCU_HVBatUndTemp_oVCU_HMIsignals_oKAMA_FP_EPSChassis1_0303: start 2, 1 bit, big-endian, i-signal-type=PRIMITIVE, init-value=0, base-type=boolean, compu {0=Cx0_False_ (False;), 1=Cx1_True}, range raw 0..1, transfer-property=PENDING
          signal VCU_DCDCFail_oVCU_HMIsignals_oKAMA_FP_EPSChassis1_0303: start 3, 1 bit, big-endian, i-signal-type=PRIMITIVE, init-value=0, base-type=boolean, compu {0=Cx0_False_ (False;), 1=Cx1_True}, range raw 0..1, transfer-property=PENDING
          signal VCU_HVBatCriFail_oVCU_HMIsignals_oKAMA_FP_EPSChassis1_0303: start 4, 1 bit, big-endian, i-signal-type=PRIMITIVE, init-value=0, base-type=boolean, compu {0=Cx0_False_ (False;), 1=Cx1_True}, range raw 0..1, transfer-property=PENDING  # Traction battery failure: GB/T 4094.2, Table 2, No. 1
          signal VCU_DriveMotOvrTemp_oVCU_HMIsignals_oKAMA_FP_EPSChassis1_0303: start 5, 1 bit, big-endian, i-signal-type=PRIMITIVE, init-value=0, base-type=boolean, compu {0=Cx0_False_ (False;), 1=Cx1_True}, range raw 0..1, transfer-property=PENDING  # Over-temp required via GB/T 19836. Additional components may be needed.
          signal VCU_DriveMotOverSpd_oVCU_HMIsignals_oKAMA_FP_EPSChassis1_0303: start 6, 1 bit, big-endian, i-signal-type=PRIMITIVE, init-value=0, base-type=boolean, compu {0=Cx0_False_ (False;), 1=Cx1_True}, range raw 0..1, transfer-property=PENDING  # Over-speeding: required via GB/T 19836
          signal VCU_CriSysFailure_oVCU_HMIsignals_oKAMA_FP_EPSChassis1_0303: start 7, 1 bit, big-endian, i-signal-type=PRIMITIVE, init-value=0, base-type=boolean, compu {0=Cx0_False_ (False;), 1=Cx1_True}, range raw 0..1, transfer-property=PENDING  # System failure tell-tale: GB/T 4094.2, Table 2, No. 3
          signal VCU_DegradedRegenBraking_oVCU_HMIsignals_oKAMA_FP_EPSChassis1_0303: start 8, 1 bit, big-endian, i-signal-type=PRIMITIVE, init-value=0, base-type=boolean, compu {0=Cx0_Nomal_Regeneration_ (Nomal Regeneration;), 1=Cx1_Degraded_Regeneration (Degraded Regeneration)}, range raw 0..1, transfer-property=PENDING  # Regenerative Braking Perfromance Degradation Display Information
          signal VCU_DegradedPerformance_oVCU_HMIsignals_oKAMA_FP_EPSChassis1_0303: start 9, 1 bit, big-endian, i-signal-type=PRIMITIVE, init-value=0, base-type=boolean, compu {0=Cx0_Nomal_Performance_ (Nomal Performance;), 1=Cx1_Degraded_Perfoemance (Degraded Perfoemance)}, range raw 0..1, transfer-property=PENDING  # Degraded Performance Display Information
          signal VCU_DrvDirCtrlFlt_oVCU_HMIsignals_oKAMA_FP_EPSChassis1_0303: start 10, 1 bit, big-endian, i-signal-type=PRIMITIVE, init-value=0, base-type=boolean, compu {0=Cx0_Drive_Control_System_Nomal_ (Drive Control System Nomal;), 1=Cx1_Drive_Control_System_Fault (Drive Control System Fault)}, range raw 0..1, transfer-property=PENDING  # Drive Direction Control Fault Flag
          signal VCU_HVBatCoolOvrTemp_oVCU_HMIsignals_oKAMA_FP_EPSChassis1_0303: start 12, 1 bit, big-endian, i-signal-type=PRIMITIVE, init-value=0, base-type=boolean, compu {0=Cx0_False_ (False;), 1=Cx1_True}, range raw 0..1, transfer-property=PENDING  # Over-temp required via GB/T 19836. Additional components may be needed.
          signal VCU_LimpHome_oVCU_HMIsignals_oKAMA_FP_EPSChassis1_0303: start 13, 1 bit, big-endian, i-signal-type=PRIMITIVE, init-value=0, base-type=boolean, compu {0=Cx0_False_ (False;), 1=Cx1_True}, range raw 0..1, transfer-property=PENDING  # Limp home: GB/T 4094.2, Table 1, No. 3
          signal VCU_HVInsulResFault_oVCU_HMIsignals_oKAMA_FP_EPSChassis1_0303: start 14, 1 bit, big-endian, i-signal-type=PRIMITIVE, init-value=0, base-type=boolean, compu {0=Cx0_False_ (False;), 1=Cx1_True}, range raw 0..1, transfer-property=PENDING  # Insulation resistance/creepage distance indication: rrequired via GB/T 19836
          signal VCU_HVBatLowSocWar_oVCU_HMIsignals_oKAMA_FP_EPSChassis1_0303: start 15, 1 bit, big-endian, i-signal-type=PRIMITIVE, init-value=0, base-type=boolean, compu {0=Cx0_False_ (False;), 1=Cx1_True}, range raw 0..1, transfer-property=PENDING  # HV Battery low SoC: GB/T 4094.2, Table 1, No. 1
          signal VCU_UnavailRegenBraking_oVCU_HMIsignals_oKAMA_FP_EPSChassis1_0303: start 23, 1 bit, big-endian, i-signal-type=PRIMITIVE, init-value=0, base-type=boolean, compu {0=Cx0_Regen_Available_ (Regen Available;), 1=Cx1_Regen_Unavailable (Regen Unavailable)}, range raw 0..1, transfer-property=PENDING  # Regeneration Unavailable Display Information
          signal VCU_FrMotorSpd_oVCU_HMIsignals_oKAMA_FP_EPSChassis1_0303: start 31, 8 bit, big-endian, i-signal-type=PRIMITIVE, init-value=0, base-type=uint8, compu {250=CxFA_Init_ (Init;), 255=CxFF_Fault, phys=raw*100 for raw 0..249; unit rpm} "Source signal range: [0,250]", range raw 0..255, unit=rpm, transfer-property=PENDING  # Front Drive Motor Speed for Display
          signal VCU_RrMotorSpd_oVCU_HMIsignals_oKAMA_FP_EPSChassis1_0303: start 39, 8 bit, big-endian, i-signal-type=PRIMITIVE, init-value=0, base-type=uint8, compu {1=Cx01_Fault_ (Fault;), 250=CxFA_Init, phys=raw*100 for raw 0..249; unit rpm}, range raw 0..250, unit=rpm, transfer-property=PENDING  # Rear Drive Motor Speed for Display
          signal VCU_InvldGearSel_oVCU_HMIsignals_oKAMA_FP_EPSChassis1_0303: start 47, 4 bit, big-endian, i-signal-type=PRIMITIVE, init-value=0, base-type=uint8, compu {0=Cx0_Oe_ (³µÁ¾Î´¾ÍÐ÷_½ûÖ¹ÇÐ»»ÐÐÊ»µµ), 1=Cx1_P_Oe_Oe_ (PµµÇÐ»»ÖÐ_Çë²ÈÖÆ¶¯), 2=Cx2_EPB_P_ (EPBÎÞÏìÓ¦_ÎÞ·¨¹ÒÈëPµµ), 3=Cx3_ss_Oe_R_ (Î£ÏÕ_³µËÙ¹ý¸ß_½ûÖ¹ÇÐ»»Rµµ), 4=Cx4_ss_Oe_P_ (Î£ÏÕ_³µËÙ¹ý¸ß_½ûÖ¹ÇÐ»»Pµµ), 5=Cx5_Oe_ (Î£ÏÕ_ÓÍÃÅÌ¤°å¿ª¶È¹ý´ó_½ûÖ¹ÇÐ»»ÐÐÊ»µµ), 6=Cx6_Oe_Oe_ (³µÁ¾´æÔÚ½ûÖ¹ÐÐÊ»¹ÊÕÏ_½ûÖ¹»»µ²), 7=Cx7_Ae_Oe_ (»»µ²Ä£¿é´æÔÚ¹ÊÕÏ_½ûÖ¹»»), 8=Cx8_Oe_ (³µÁ¾¼ì²âµ½²åÇ¹_½ûÖ¹ÇÐ»»µµ), 9=Cx9_Oe_ (³µÁ¾µç×Ó×¤³µÊ§Ð§_½ûÖ¹ÇÐ»»)}, range raw 0..15, transfer-property=PENDING  # Invalid Gear Selection Flag
          signal MessageCounter_27B_oVCU_HMIsignals_oKAMA_FP_EPSChassis1_0303: start 51, 4 bit, big-endian, i-signal-type=PRIMITIVE, init-value=0, base-type=uint8, compu {identical}, range raw 0..7, transfer-property=PENDING  # AliveCounter_xxx
          signal Checksum_27B_oVCU_HMIsignals_oKAMA_FP_EPSChassis1_0303: start 63, 8 bit, big-endian, i-signal-type=PRIMITIVE, init-value=0, base-type=uint8, compu {identical}, range raw 0..255, transfer-property=PENDING  # CRC-XXX
      frame VCU_HVbattStatus1_oKAMA_FP_EPSChassis1_0303: id 0x27C, from VCU, frame-length=8, can-addressing-mode=STANDARD
        pdu VCU_HVbattStatus1_oKAMA_FP_EPSChassis1_0303: length=8, minimum-delay=0, transmission-mode-false-timing=cyclic-timing={time-offset=0, time-period=0.2}, transmission-mode-true-timing=cyclic-timing={time-offset=0, time-period=0.2}, unused-bit-pattern=0
          signal VCU_AvaDrvRange_oVCU_HVbattStatus1_oKAMA_FP_EPSChassis1_0303: start 7, 10 bit, big-endian, i-signal-type=PRIMITIVE, init-value=0, base-type=uint16, compu {1022=Cx3FE_Initializing_ (Initializing;), 1023=Cx3FF_Error; unit km}, range raw 0..1023, unit=km, transfer-property=PENDING  # Available driving range to the user.
          signal VCU_EnergyReturnedRegen_oVCU_HVbattStatus1_oKAMA_FP_EPSChassis1_0303: start 9, 10 bit, big-endian, i-signal-type=PRIMITIVE, init-value=0, base-type=uint16, compu {254=Cx0FE_Init_ (Init;), 255=Cx0FF_Error, phys=raw*0.1 for raw 0..1000; unit kWh}, range raw 0..1000, unit=kWh, transfer-property=PENDING  # Total electrical energy recovered by regeneration in the current drive cycle.
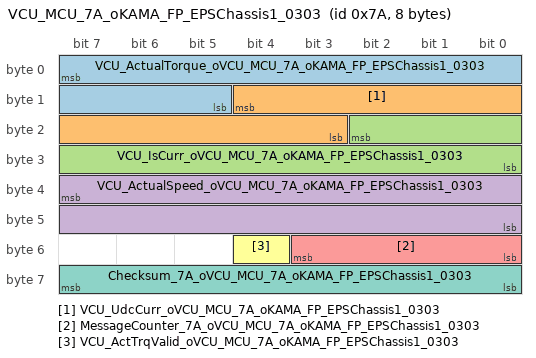
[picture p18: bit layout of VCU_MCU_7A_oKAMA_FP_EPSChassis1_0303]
      frame VCU_MCU_7A_oKAMA_FP_EPSChassis1_0303: id 0x7A, from VCU, frame-length=8, can-addressing-mode=STANDARD
        pdu VCU_MCU_7A_oKAMA_FP_EPSChassis1_0303: length=8, minimum-delay=0, transmission-mode-false-timing=cyclic-timing={time-offset=0, time-period=0.01}, transmission-mode-true-timing=cyclic-timing={time-offset=0, time-period=0.01}, unused-bit-pattern=0
          signal VCU_ActualTorque_oVCU_MCU_7A_oKAMA_FP_EPSChassis1_0303: start 7, 11 bit, big-endian, i-signal-type=PRIMITIVE, init-value=1024, base-type=uint16, compu {phys=raw-1024 for raw 0..2047}, range raw 0..2047, transfer-property=PENDING  # the actual torque of motorµç»úÊµÊ±Á¦¾Ø
          signal VCU_UdcCurr_oVCU_MCU_7A_oKAMA_FP_EPSChassis1_0303: start 12, 10 bit, big-endian, i-signal-type=PRIMITIVE, init-value=0, base-type=uint16, compu {identical}, range raw 0..1021, transfer-property=PENDING  # the actual voltage of udclinkÊµÊ±Ö±Á÷µçÑ¹
          signal VCU_IsCurr_oVCU_MCU_7A_oKAMA_FP_EPSChassis1_0303: start 18, 11 bit, big-endian, i-signal-type=PRIMITIVE, init-value=0, base-type=uint16, compu {phys=raw*0.5 for raw 0..2045}, range raw 0..2045, transfer-property=PENDING  # the actual current ÊµÊ±Ö±Á÷µçÁ÷£¨¹ÀËãµçÁ÷£©
          signal VCU_ActualSpeed_oVCU_MCU_7A_oKAMA_FP_EPSChassis1_0303: start 39, 16 bit, big-endian, i-signal-type=PRIMITIVE, init-value=32768, base-type=uint16, compu {phys=raw-32768 for raw 0..65535}, range raw 0..65535, transfer-property=PENDING  # the actual motor speedµç»úÊµÊ±×ªËÙ
          signal MessageCounter_7A_oVCU_MCU_7A_oKAMA_FP_EPSChassis1_0303: start 51, 4 bit, big-endian, i-signal-type=PRIMITIVE, init-value=0, base-type=uint8, compu {identical}, range raw 0..15, transfer-property=PENDING  # rolling counter
          signal VCU_ActTrqValid_oVCU_MCU_7A_oKAMA_FP_EPSChassis1_0303: start 52, 1 bit, big-endian, i-signal-type=PRIMITIVE, init-value=0, base-type=boolean, compu {0=Cx0_invalid, 1=Cx1_valid}, range raw 0..1, transfer-property=PENDING  # Actual torque valid
          signal Checksum_7A_oVCU_MCU_7A_oKAMA_FP_EPSChassis1_0303: start 63, 8 bit, big-endian, i-signal-type=PRIMITIVE, init-value=0, base-type=uint8, compu {identical}, range raw 0..255, transfer-property=PENDING  # checksum
      frame VCU_OdometerInfo_oKAMA_FP_EPSChassis1_0303: id 0x279, from VCU, frame-length=3, can-addressing-mode=STANDARD
        pdu VCU_OdometerInfo_oKAMA_FP_EPSChassis1_0303: length=3, minimum-delay=0, transmission-mode-false-timing=cyclic-timing={time-offset=0, time-period=2}, transmission-mode-true-timing=cyclic-timing={time-offset=0, time-period=2}, unused-bit-pattern=0
          signal VCU_OdometerInfo_VCU_oVCU_OdometerInfo_oKAMA_FP_EPSChassis1_0303: start 7, 20 bit, big-endian, i-signal-type=PRIMITIVE, init-value=0, base-type=uint32, compu {identical}, range raw 0..1048575, unit=km, transfer-property=PENDING  # odometer
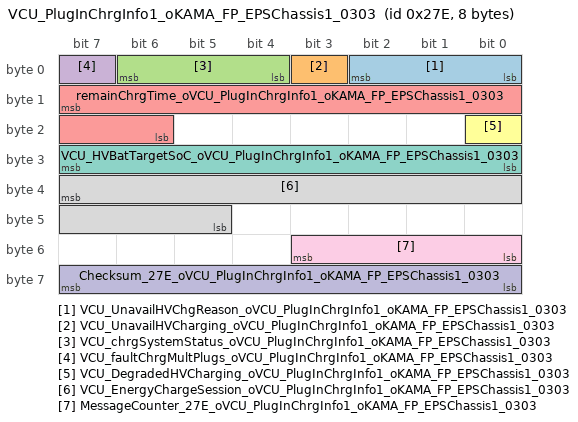
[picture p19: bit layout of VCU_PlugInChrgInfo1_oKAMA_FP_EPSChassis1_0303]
      frame VCU_PlugInChrgInfo1_oKAMA_FP_EPSChassis1_0303: id 0x27E, from VCU, frame-length=8, can-addressing-mode=STANDARD
        pdu VCU_PlugInChrgInfo1_oKAMA_FP_EPSChassis1_0303: length=8, minimum-delay=0, transmission-mode-false-timing=cyclic-timing={time-offset=0, time-period=0.5}, transmission-mode-true-timing=cyclic-timing={time-offset=0, time-period=0.5}, unused-bit-pattern=0
          signal VCU_UnavailHVChgReason_oVCU_PlugInChrgInfo1_oKAMA_FP_EPSChassis1_0303: start 2, 3 bit, big-endian, i-signal-type=PRIMITIVE, init-value=0, base-type=uint8, compu {0=Cx0_Not_Fault_ (Not Fault;), 1=Cx1_OBC_Fault_ (OBC Fault;), 2=Cx2_Insufficient_AC_Power_Supply_ (Insufficient AC Power Supply;), 3=Cx3_AC_Offboard_Fault_ (AC Offboard Fault;), 4=Cx4_DC_Offboard_Fault_ (DC Offboard Fault;), 5=Cx5_Reserved_ (Reserved;), 6=Cx6_Reserved_ (Reserved;), 7=Cx7_Other_Fault (Other Fault)}, range raw 0..7, transfer-property=PENDING  # HV Battery Charging Fault Reason
          signal VCU_UnavailHVCharging_oVCU_PlugInChrgInfo1_oKAMA_FP_EPSChassis1_0303: start 3, 1 bit, big-endian, i-signal-type=PRIMITIVE, init-value=0, base-type=boolean, compu {1=Cx1_Charging_Unvailable (Charging Unvailable)}, range raw 0..1, transfer-property=PENDING  # Charging Availability Flag
          signal VCU_chrgSystemStatus_oVCU_PlugInChrgInfo1_oKAMA_FP_EPSChassis1_0303: start 6, 3 bit, big-endian, i-signal-type=PRIMITIVE, init-value=0, base-type=uint8, compu {1=Cx1_Off_Plug_ (Off Plug;), 2=Cx2_Plug_Detected_ (Plug Detected;), 3=Cx3_Charging_Standby_ (Charging Standby;), 4=Cx4_AC_Charging_ (AC Charging;), 5=Cx5_DC_Charging_ (DC Charging;), 6=Cx6_Charging_Completed_ (Charging Completed;), 7=Cx7_Fault}, range raw 0..7, transfer-property=PENDING
          signal VCU_faultChrgMultPlugs_oVCU_PlugInChrgInfo1_oKAMA_FP_EPSChassis1_0303: start 7, 1 bit, big-endian, i-signal-type=PRIMITIVE, init-value=0, base-type=boolean, compu {0=Cx0_False_ (False;), 1=Cx1_True}, range raw 0..1, transfer-property=PENDING
          signal remainChrgTime_oVCU_PlugInChrgInfo1_oKAMA_FP_EPSChassis1_0303: start 15, 10 bit, big-endian, i-signal-type=PRIMITIVE, init-value=0, base-type=uint16, compu {1022=Cx3FE_Init_ (Init;), 1023=Cx3FF_Error, phys=raw*0.5 for raw 0..1000} "Source signal range: [0,1000]", range raw 0..1023, transfer-property=PENDING
          signal VCU_DegradedHVCharging_oVCU_PlugInChrgInfo1_oKAMA_FP_EPSChassis1_0303: start 16, 1 bit, big-endian, i-signal-type=PRIMITIVE, init-value=0, base-type=boolean, compu {0=Cx0_Full_Charge_Performance_ (Full Charge Performance;)}, range raw 0..1, transfer-property=PENDING  # Charging Performance Flag
          signal VCU_HVBatTargetSoC_oVCU_PlugInChrgInfo1_oKAMA_FP_EPSChassis1_0303: start 31, 8 bit, big-endian, i-signal-type=PRIMITIVE, init-value=0, base-type=uint8, compu {254=CxFE_Init_ (Init;), 255=CxFF_Fault, phys=raw*0.5 for raw 0..253; unit %}, range raw 0..255, unit=%, transfer-property=PENDING  # HV Battery Target SoC Feedback from Customer Setting
          signal VCU_EnergyChargeSession_oVCU_PlugInChrgInfo1_oKAMA_FP_EPSChassis1_0303: start 39, 11 bit, big-endian, i-signal-type=PRIMITIVE, init-value=0, base-type=uint16, compu {2046=Cx7FE_Init_ (Init;), 2047=Cx7FF_Fault, phys=raw*0.1 for raw 0..2000; unit kWh} "Source signal range: [0,2000]", range raw 0..2047, unit=kWh, transfer-property=PENDING  # Total electrical energy accumulated in the current charge session
          signal MessageCounter_27E_oVCU_PlugInChrgInfo1_oKAMA_FP_EPSChassis1_0303: start 51, 4 bit, big-endian, i-signal-type=PRIMITIVE, init-value=0, base-type=uint8, compu {identical}, range raw 0..7, transfer-property=PENDING  # AliveCounter_xxx
          signal Checksum_27E_oVCU_PlugInChrgInfo1_oKAMA_FP_EPSChassis1_0303: start 63, 8 bit, big-endian, i-signal-type=PRIMITIVE, init-value=0, base-type=uint8, compu {identical}, range raw 0..255, transfer-property=PENDING  # CRC-XXX
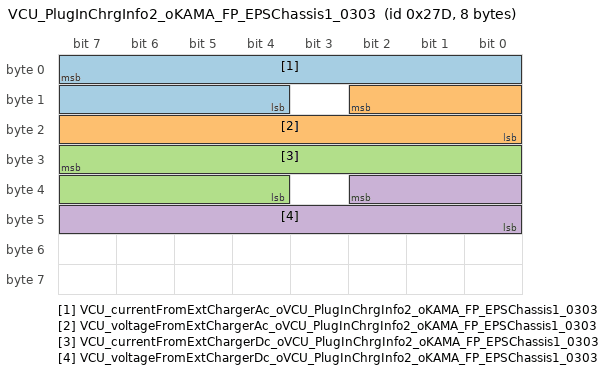
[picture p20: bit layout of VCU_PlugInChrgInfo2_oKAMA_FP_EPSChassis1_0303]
      frame VCU_PlugInChrgInfo2_oKAMA_FP_EPSChassis1_0303: id 0x27D, from VCU, frame-length=8, can-addressing-mode=STANDARD
        pdu VCU_PlugInChrgInfo2_oKAMA_FP_EPSChassis1_0303: length=8, minimum-delay=0, transmission-mode-false-timing=cyclic-timing={time-offset=0, time-period=0.2}, transmission-mode-true-timing=cyclic-timing={time-offset=0, time-period=0.2}, unused-bit-pattern=0
          signal VCU_currentFromExtChargerAc_oVCU_PlugInChrgInfo2_oKAMA_FP_EPSChassis1_0303: start 7, 12 bit, big-endian, i-signal-type=PRIMITIVE, init-value=0, base-type=uint16, compu {4094=CxFFE_Initializing_ (Initializing;), 4095=CxFFF_Error, phys=raw*0.5 for raw 0..4093; unit A} "Source signal range: [0,4093]", range raw 0..4095, unit=A, transfer-property=PENDING
          signal VCU_voltageFromExtChargerAc_oVCU_PlugInChrgInfo2_oKAMA_FP_EPSChassis1_0303: start 10, 11 bit, big-endian, i-signal-type=PRIMITIVE, init-value=0, base-type=uint16, compu {2046=Cx7FE_Initializing_ (Initializing;), 2047=Cx7FF_Error, phys=raw*0.5 for raw 0..2000; unit V} "Source signal range: [0,2000]", range raw 0..2047, unit=V, transfer-property=PENDING
          signal VCU_currentFromExtChargerDc_oVCU_PlugInChrgInfo2_oKAMA_FP_EPSChassis1_0303: start 31, 12 bit, big-endian, i-signal-type=PRIMITIVE, init-value=0, base-type=uint16, compu {4094=CxFFE_Initializing_ (Initializing;), 4095=CxFFF_Error, phys=raw*0.5 for raw 0..4093; unit A} "Source signal range: [0,4093]", range raw 0..4095, unit=A, transfer-property=PENDING
          signal VCU_voltageFromExtChargerDc_oVCU_PlugInChrgInfo2_oKAMA_FP_EPSChassis1_0303: start 34, 11 bit, big-endian, i-signal-type=PRIMITIVE, init-value=0, base-type=uint16, compu {2046=Cx7FE_Initializing_ (Initializing;), 2047=Cx7FF_Error, phys=raw*0.5 for raw 0..2000; unit V} "Source signal range: [0,2000]", range raw 0..2047, unit=V, transfer-property=PENDING
      frame VCU_PwrtrainHVbattStatus2_oKAMA_FP_EPSChassis1_0303: id 0x27F, from VCU, frame-length=8, can-addressing-mode=STANDARD
        pdu VCU_PwrtrainHVbattStatus2_oKAMA_FP_EPSChassis1_0303: length=8, minimum-delay=0, transmission-mode-false-timing=cyclic-timing={time-offset=0, time-period=0.2}, transmission-mode-true-timing=cyclic-timing={time-offset=0, time-period=0.2}, unused-bit-pattern=0
          signal VCU_HVBatCurrent_VCU_oVCU_PwrtrainHVbattStatus2_oKAMA_FP_EPSChassis1_0303: start 15, 14 bit, big-endian, i-signal-type=PRIMITIVE, init-value=8190, base-type=uint16, compu {16382=Cx3FFE_Init_ (Init;), 16383=Cx3FFF_Error, phys=raw*0.5-4095 for raw 0..16381; unit A} "Source signal range: [0,16382]", range raw 0..16383, unit=A, transfer-property=PENDING  # HV Battery current: required via GB/T 19836
          signal VCU_HVBatVolt_VCU_oVCU_PwrtrainHVbattStatus2_oKAMA_FP_EPSChassis1_0303: start 31, 12 bit, big-endian, i-signal-type=PRIMITIVE, init-value=0, base-type=uint16, compu {4094=CxFFE_Init_ (Init;), 4095=CxFFF_Error, phys=raw*0.25 for raw 0..4093; unit V} "Source signal range: [0,4093]", range raw 0..4095, unit=V, transfer-property=PENDING  # HV Battery voltage: required via GB/T 19836
          signal MessageCounter_27F_oVCU_PwrtrainHVbattStatus2_oKAMA_FP_EPSChassis1_0303: start 51, 4 bit, big-endian, i-signal-type=PRIMITIVE, init-value=0, base-type=uint8, compu {identical}, range raw 0..7, transfer-property=PENDING  # AliveCounter_xxx
          signal Checksum_27F_oVCU_PwrtrainHVbattStatus2_oKAMA_FP_EPSChassis1_0303: start 63, 8 bit, big-endian, i-signal-type=PRIMITIVE, init-value=0, base-type=uint8, compu {identical}, range raw 0..255, transfer-property=PENDING  # CRC-XXX
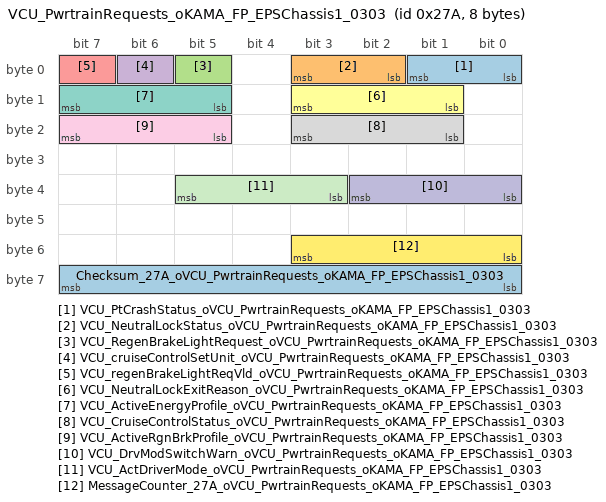
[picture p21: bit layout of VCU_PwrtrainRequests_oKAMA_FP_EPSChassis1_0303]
      frame VCU_PwrtrainRequests_oKAMA_FP_EPSChassis1_0303: id 0x27A, from VCU, frame-length=8, can-addressing-mode=STANDARD
        pdu VCU_PwrtrainRequests_oKAMA_FP_EPSChassis1_0303: length=8, minimum-delay=0, transmission-mode-false-timing=cyclic-timing={time-offset=0, time-period=0.1}, transmission-mode-true-timing=cyclic-timing={time-offset=0, time-period=0.1}, unused-bit-pattern=0
          signal VCU_PtCrashStatus_oVCU_PwrtrainRequests_oKAMA_FP_EPSChassis1_0303: start 1, 2 bit, big-endian, i-signal-type=PRIMITIVE, init-value=0, base-type=uint8, compu {0=Cx0_No_Crash_ (No Crash;), 1=Cx1_Soft_Crash_ (Soft Crash;), 2=Cx2_Severe_Crash_ (Severe Crash;), 3=Cx3_Fault}, range raw 0..3, transfer-property=PENDING  # Powertrain Crash Detection Signal Status
          signal VCU_NeutralLockStatus_oVCU_PwrtrainRequests_oKAMA_FP_EPSChassis1_0303: start 3, 2 bit, big-endian, i-signal-type=PRIMITIVE, init-value=0, base-type=uint8, compu {0=Cx0_Unavailable_ (Unavailable;), 1=Cx1_Available_ (Available;), 2=Cx2_On_ (On;), 3=Cx3_Reserved}, range raw 0..3, transfer-property=PENDING  # Neutral Lock Status
          signal VCU_RegenBrakeLightRequest_oVCU_PwrtrainRequests_oKAMA_FP_EPSChassis1_0303: start 5, 1 bit, big-endian, i-signal-type=PRIMITIVE, init-value=0, base-type=boolean, compu {0=Cx0_Brake_lights_Off (Brake lights Off), 1=Cx1_Brake_lights_On (Brake lights On)}, range raw 0..1, transfer-property=PENDING  # Request to illuminate the brake lights from the Powertrain if regen creates deceleration greater than 0.07g.
          signal VCU_cruiseControlSetUnit_oVCU_PwrtrainRequests_oKAMA_FP_EPSChassis1_0303: start 6, 1 bit, big-endian, i-signal-type=PRIMITIVE, init-value=0, base-type=boolean, compu {0=Cx0_Km_h_ (Km/h;), 1=Cx1_MPH}, range raw 0..1, transfer-property=PENDING  # Cruise Control Set Unit for Display
          signal VCU_regenBrakeLightReqVld_oVCU_PwrtrainRequests_oKAMA_FP_EPSChassis1_0303: start 7, 1 bit, big-endian, i-signal-type=PRIMITIVE, init-value=0, base-type=boolean, compu {0=Cx0_Brake_lights_Off_ (Brake lights Off;), 1=Cx1_Brake_lights_On (Brake lights On)}, range raw 0..1, transfer-property=PENDING
          signal VCU_NeutralLockExitReason_oVCU_PwrtrainRequests_oKAMA_FP_EPSChassis1_0303: start 11, 3 bit, big-endian, i-signal-type=PRIMITIVE, init-value=0, base-type=uint8, compu {0=Cx0_None_ (None;), 1=Cx1_User_ (User;), 2=Cx2_Time_Out_ (Time Out;), 3=Cx3_Speed_Exceeded_ (Speed Exceeded;), 4=Cx4_Reserved_ (Reserved;), 5=Cx5_Reserved_ (Reserved;), 6=Cx6_Reserved_ (Reserved;), 7=Cx7_System_Fault (System Fault)}, range raw 0..7, transfer-property=PENDING  # Neutral Lock Exit Reason
          signal VCU_ActiveEnergyProfile_oVCU_PwrtrainRequests_oKAMA_FP_EPSChassis1_0303: start 15, 3 bit, big-endian, i-signal-type=PRIMITIVE, init-value=0, base-type=uint8, compu {0=Cx0_Comfort_ (Comfort;), 1=Cx1_Eco_ (Eco;), 2=Cx2_Resserved_ (Resserved;), 3=Cx3_On_ (On;), 4=Cx4_Reserved_ (Reserved;), 5=Cx5_Reserved_ (Reserved;), 6=Cx6_Reserved_ (Reserved;), 7=Cx7_Fault}, range raw 0..7, transfer-property=PENDING  # Active Energy Profile
          signal VCU_CruiseControlStatus_oVCU_PwrtrainRequests_oKAMA_FP_EPSChassis1_0303: start 19, 3 bit, big-endian, i-signal-type=PRIMITIVE, init-value=0, base-type=uint8, compu {0=Cx0_Inactive_ (Inactive;), 1=Cx1_Standyby_ (Standyby;), 2=Cx2_Engaged_ (Engaged;), 3=Cx3_Reserved_ (Reserved;), 4=Cx4_Reserved_ (Reserved;), 5=Cx5_Reserved_ (Reserved;), 6=Cx6_Reserved_ (Reserved;), 7=Cx7_Fault}, range raw 0..7, transfer-property=PENDING  # Cruise Control Status
          signal VCU_ActiveRgnBrkProfile_oVCU_PwrtrainRequests_oKAMA_FP_EPSChassis1_0303: start 23, 3 bit, big-endian, i-signal-type=PRIMITIVE, init-value=0, base-type=uint8, compu {0=Cx0_Low_ (Low;), 1=Cx1_High_ (High;), 2=Cx2_Reserved_ (Reserved;), 3=Cx3_Reserved_ (Reserved;), 4=Cx4_Reserved_ (Reserved;), 5=Cx5_Reserved_ (Reserved;), 6=Cx6_Reserved_ (Reserved;), 7=Cx7_Fault}, range raw 0..7, transfer-property=PENDING  # Active Regenerative Braking Profile
          signal VCU_DrvModSwitchWarn_oVCU_PwrtrainRequests_oKAMA_FP_EPSChassis1_0303: start 34, 3 bit, big-endian, i-signal-type=PRIMITIVE, init-value=0, base-type=uint8, compu {0=Cx0_RESERVE_, 1=Cx1_unrecommed_Sport_Low_SOC (unrecommed Sport-Low SOC), 2=Cx2_unrecommed_Vehicle_Fault (unrecommed-Vehicle Fault)}, range raw 0..7, transfer-property=PENDING  # ¼ÝÊ»Ä£Ê½ÇÐ»»Òì³£ÌáÊ¾
          signal VCU_ActDriverMode_oVCU_PwrtrainRequests_oKAMA_FP_EPSChassis1_0303: start 37, 3 bit, big-endian, i-signal-type=PRIMITIVE, init-value=0, base-type=uint8, compu {0=Cx0_ECO_Mode (ECO Mode), 1=Cx1_Reserved, 2=Cx2_Sport}, range raw 0..7, transfer-property=PENDING  # Êµ¼Ê¼ÝÊ»Ä£Ê½
          signal MessageCounter_27A_oVCU_PwrtrainRequests_oKAMA_FP_EPSChassis1_0303: start 51, 4 bit, big-endian, i-signal-type=PRIMITIVE, init-value=0, base-type=uint8, compu {identical}, range raw 0..7, transfer-property=PENDING  # AliveCounter_xxx
          signal Checksum_27A_oVCU_PwrtrainRequests_oKAMA_FP_EPSChassis1_0303: start 63, 8 bit, big-endian, i-signal-type=PRIMITIVE, init-value=0, base-type=uint8, compu {identical}, range raw 0..255, transfer-property=PENDING  # CRC-XXX
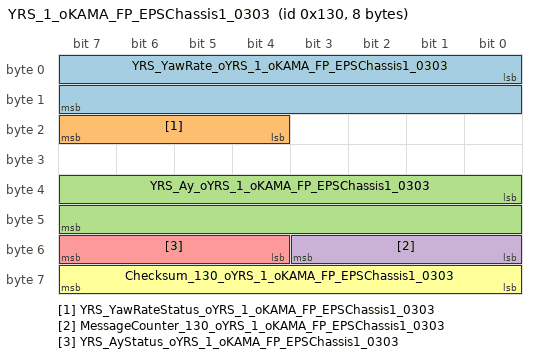
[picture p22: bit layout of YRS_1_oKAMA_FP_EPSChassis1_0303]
      frame YRS_1_oKAMA_FP_EPSChassis1_0303: id 0x130, to VCU, frame-length=8, can-addressing-mode=STANDARD
        pdu YRS_1_oKAMA_FP_EPSChassis1_0303: length=8, minimum-delay=0, transmission-mode-false-timing=cyclic-timing={time-offset=0, time-period=0.02}, transmission-mode-true-timing=cyclic-timing={time-offset=0, time-period=0.02}, unused-bit-pattern=0
          signal YRS_YawRate_oYRS_1_oKAMA_FP_EPSChassis1_0303: start 0, 16 bit, little-endian, i-signal-type=PRIMITIVE, init-value=32768, base-type=uint16, compu {phys=raw*0.005-163.84 for raw 0..65534; unit ¡ã/s}, range raw 0..65534, unit=¡ã/s, transfer-property=PENDING, to VCU  # ºá°Ú½ÇËÙ¶ÈÐÅºÅ
          signal YRS_YawRateStatus_oYRS_1_oKAMA_FP_EPSChassis1_0303: start 20, 4 bit, little-endian, i-signal-type=PRIMITIVE, init-value=0, base-type=uint8, compu {0=Cx0_Valid, 1=Cx1_Sensor_not_available (Sensor not available), 2=Cx2_Signal_failure (Signal failure)}, range raw 0..15, transfer-property=PENDING, to VCU  # ºá°Ú½ÇËÙ¶È×´Ì¬ÐÅºÅ
          signal YRS_Ay_oYRS_1_oKAMA_FP_EPSChassis1_0303: start 32, 16 bit, little-endian, i-signal-type=PRIMITIVE, init-value=32784.9293563579, base-type=uint16, compu {phys=raw*0.0001274-4.1768 for raw 0..65535; unit g/digit}, range raw 0..65535, unit=g/digit, transfer-property=PENDING, to VCU  # ²àÏò¼ÓËÙ¶ÈÐÅºÅ
          signal MessageCounter_130_oYRS_1_oKAMA_FP_EPSChassis1_0303: start 48, 4 bit, little-endian, i-signal-type=PRIMITIVE, init-value=0, base-type=uint8, compu {identical}, range raw 0..15, transfer-property=PENDING, to VCU  # YRS1±¨ÎÄÉúÃüÐÅºÅ
          signal YRS_AyStatus_oYRS_1_oKAMA_FP_EPSChassis1_0303: start 52, 4 bit, little-endian, i-signal-type=PRIMITIVE, init-value=0, base-type=uint8, compu {0=Cx0_Valid, 1=Cx1_Sensor_not_available (Sensor not available), 2=Cx2_Signal_failure (Signal failure)}, range raw 0..15, transfer-property=PENDING, to VCU  # ²àÏò¼ÓËÙ¶È×´Ì¬ÐÅºÅ
          signal Checksum_130_oYRS_1_oKAMA_FP_EPSChassis1_0303: start 56, 8 bit, little-endian, i-signal-type=PRIMITIVE, init-value=0, base-type=uint8, compu {identical}, range raw 0..255, transfer-property=PENDING, to VCU  # CRC J1850Ëã·¨Ð£ÑéËã·¨
      frame YRS_2_oKAMA_FP_EPSChassis1_0303: id 0x131, to VCU, frame-length=8, can-addressing-mode=STANDARD
        pdu YRS_2_oKAMA_FP_EPSChassis1_0303: length=8, minimum-delay=0, transmission-mode-false-timing=cyclic-timing={time-offset=0, time-period=0.02}, transmission-mode-true-timing=cyclic-timing={time-offset=0, time-period=0.02}, unused-bit-pattern=0
          signal YRS_Ax_oYRS_2_oKAMA_FP_EPSChassis1_0303: start 32, 16 bit, little-endian, i-signal-type=PRIMITIVE, init-value=32784.9293563579, base-type=uint16, compu {phys=raw*0.0001274-4.1768 for raw 0..65535; unit g/digit}, range raw 0..65535, unit=g/digit, transfer-property=PENDING, to VCU  # ×ÝÏò¼ÓËÙ¶ÈÐÅºÅ
          signal MessageCounter_131_oYRS_2_oKAMA_FP_EPSChassis1_0303: start 48, 4 bit, little-endian, i-signal-type=PRIMITIVE, init-value=0, base-type=uint8, compu {identical}, range raw 0..15, transfer-property=PENDING, to VCU  # YRS2±¨ÎÄÉúÃüÐÅºÅ
          signal YRS_AxStatus_oYRS_2_oKAMA_FP_EPSChassis1_0303: start 52, 4 bit, little-endian, i-signal-type=PRIMITIVE, init-value=0, base-type=uint8, compu {0=Cx0_Valid, 1=Cx1_Sensor_not_available (Sensor not available), 2=Cx2_Signal_failure (Signal failure)}, range raw 0..15, transfer-property=PENDING, to VCU  # ×ÝÏò¼ÓËÙ¶È×´Ì¬ÐÅºÅ
          signal Checksum_131_oYRS_2_oKAMA_FP_EPSChassis1_0303: start 56, 8 bit, little-endian, i-signal-type=PRIMITIVE, init-value=0, base-type=uint8, compu {identical}, range raw 0..255, transfer-property=PENDING, to VCU  # CRC J1850Ëã·¨Ð£ÑéËã·¨
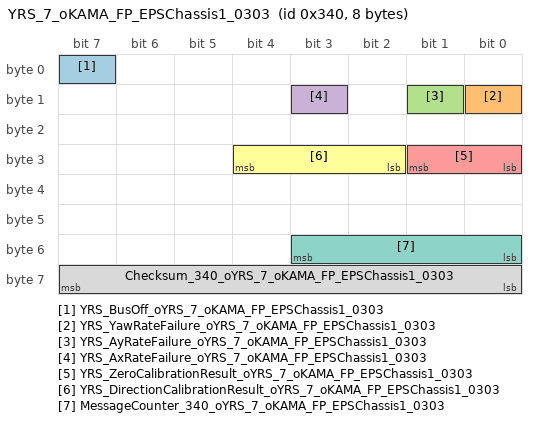
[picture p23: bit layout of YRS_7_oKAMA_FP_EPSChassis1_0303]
      frame YRS_7_oKAMA_FP_EPSChassis1_0303: id 0x340, to VCU, frame-length=8, can-addressing-mode=STANDARD
        pdu YRS_7_oKAMA_FP_EPSChassis1_0303: length=8, minimum-delay=0, transmission-mode-false-timing=cyclic-timing={time-offset=0, time-period=0.1}, transmission-mode-true-timing=cyclic-timing={time-offset=0, time-period=0.1}, unused-bit-pattern=0
          signal YRS_BusOff_oYRS_7_oKAMA_FP_EPSChassis1_0303: start 7, 1 bit, little-endian, i-signal-type=PRIMITIVE, init-value=0, base-type=boolean, compu {0=Cx0_No_Bus_Off_ (No Bus-Off;), 1=Cx1_Bus_Off (Bus-Off)}, range raw 0..1, transfer-property=PENDING, to VCU  # Bus Off±êÖ¾Î»
          signal YRS_YawRateFailure_oYRS_7_oKAMA_FP_EPSChassis1_0303: start 8, 1 bit, little-endian, i-signal-type=PRIMITIVE, init-value=0, base-type=boolean, compu {0=Cx0_No_Failure_ (No Failure;), 1=Cx1_Failure}, range raw 0..1, transfer-property=PENDING, to VCU  # ºá°Ú½ÇËÙ¶È´íÎó±êÖ¾Î»
          signal YRS_AyRateFailure_oYRS_7_oKAMA_FP_EPSChassis1_0303: start 9, 1 bit, little-endian, i-signal-type=PRIMITIVE, init-value=0, base-type=boolean, compu {0=Cx0_No_Failure_ (No Failure;), 1=Cx1_Failure}, range raw 0..1, transfer-property=PENDING, to VCU  # ²àÏò¼ÓËÙ¶È´íÎó±êÖ¾Î»
          signal YRS_AxRateFailure_oYRS_7_oKAMA_FP_EPSChassis1_0303: start 11, 1 bit, little-endian, i-signal-type=PRIMITIVE, init-value=0, base-type=boolean, compu {identical}, range raw 0..1, transfer-property=PENDING, to VCU  # ×ÝÏò¼ÓËÙ¶È´íÎó±êÖ¾Î»
          signal YRS_ZeroCalibrationResult_oYRS_7_oKAMA_FP_EPSChassis1_0303: start 24, 2 bit, little-endian, i-signal-type=PRIMITIVE, init-value=0, base-type=uint8, compu {0=Cx0_Oe_ (³õÊ¼Öµ), 1=Cx1_ (±êÁã³É¹¦), 2=Cx2_Oe_ (±êÁãÖµ³É¹¦Çå³ý)}, range raw 0..2, transfer-property=PENDING, to VCU  # Áãµã±ê¶¨½á¹û±êÖ¾Î»
          signal YRS_DirectionCalibrationResult_oYRS_7_oKAMA_FP_EPSChassis1_0303: start 26, 3 bit, little-endian, i-signal-type=PRIMITIVE, init-value=0, base-type=uint8, compu {0=Cx0_Ae_ (³¯Ç°(ÕýÃæ Ä¬ÈÏ)), 1=Cx1_ (³¯×ó(ÕýÃæ)), 2=Cx2_ (³¯ºó(ÕýÃæ)), 3=Cx3_ (³¯ÓÒ(ÕýÃæ)), 4=Cx4_ (³¯Ç°(·´Ãæ)), 5=Cx5_ (³¯×ó(·´Ãæ)), 6=Cx6_ (³¯ºó(·´Ãæ)), 7=Cx7_ (³¯ÓÒ(·´Ãæ))}, range raw 0..7, transfer-property=PENDING, to VCU  # ·½Ïò±ê¶¨½á¹û±êÖ¾Î»
          signal MessageCounter_340_oYRS_7_oKAMA_FP_EPSChassis1_0303: start 48, 4 bit, little-endian, i-signal-type=PRIMITIVE, init-value=0, base-type=uint8, compu {identical}, range raw 0..15, transfer-property=PENDING, to VCU  # YRS7±¨ÎÄÉúÃüÐÅºÅ
          signal Checksum_340_oYRS_7_oKAMA_FP_EPSChassis1_0303: start 56, 8 bit, little-endian, i-signal-type=PRIMITIVE, init-value=0, base-type=uint8, compu {identical}, range raw 0..255, transfer-property=PENDING, to VCU  # CRC J1850Ëã·¨Ð£ÑéËã·¨
